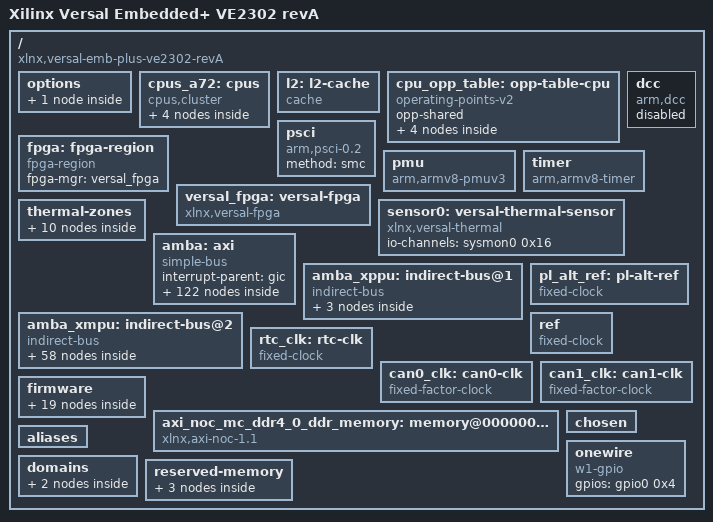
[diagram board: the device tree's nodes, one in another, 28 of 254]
/dts-v1/;
/ {
        compatible = "xlnx,versal-emb-plus-ve2302-revA", "xlnx,versal-emb-plus-ve2302", "xlnx,versal";
        #address-cells = <0x2>;
        #size-cells = <0x2>;
        model = "Xilinx Versal Embedded+ VE2302 revA";
        board = "v80";
        device_id = "xcv80";
        slrcount = <0x3>;
        family = "Versal";
        speed_grade = "2MHP";

        options {

                u-boot {
                        compatible = "u-boot,config";
                        bootscr-address = /bits/ 64 <0x20000000>;
                };
        };

        cpus_a72: cpus {
                phandle = <0xc3>;
                #address-cells = <0x1>;
                #size-cells = <0x0>;
                compatible = "cpus,cluster";
                #ranges-address-cells = <0x2>;
                #ranges-size-cells = <0x2>;

                psv_cortexa72_0: cpu@0 {
                        phandle = <0xbd>;
                        compatible = "arm,cortex-a72", "arm,armv8";
                        device_type = "cpu";
                        enable-method = "psci";
                        operating-points-v2 = <&cpu_opp_table>;
                        reg = <0x0>;
                        cpu-idle-states = <&CPU_SLEEP_0>;
                        power-domains = <&versal_firmware 0x18110003>;
                        d-cache-size = <0x8000>;
                        d-cache-line-size = <0x40>;
                        d-cache-sets = <0x100>;
                        i-cache-size = <0xc000>;
                        i-cache-line-size = <0x40>;
                        i-cache-sets = <0x100>;
                        next-level-cache = <&l2>;
                        clocks = <&versal_clk 0x4d>;
                        xlnx,timestamp-clk-freq = <0x5f5e100>;
                        xlnx,pss-ref-clk-freq = <0x1fca055>;
                        stamp-frequency = <0x5f5e100>;
                        xlnx,ip-name = "psv_cortexa72";
                        xlnx,cpu-clk-freq-hz = <0x62590006>;
                        cpu-frequency = <0x62590006>;
                        bus-handle = <0x1>;
                };

                psv_cortexa72_1: cpu@1 {
                        phandle = <0xbf>;
                        compatible = "arm,cortex-a72", "arm,armv8";
                        device_type = "cpu";
                        enable-method = "psci";
                        operating-points-v2 = <&cpu_opp_table>;
                        reg = <0x1>;
                        cpu-idle-states = <&CPU_SLEEP_0>;
                        power-domains = <&versal_firmware 0x18110004>;
                        d-cache-size = <0x8000>;
                        d-cache-line-size = <0x40>;
                        d-cache-sets = <0x100>;
                        i-cache-size = <0xc000>;
                        i-cache-line-size = <0x40>;
                        i-cache-sets = <0x100>;
                        next-level-cache = <&l2>;
                        xlnx,timestamp-clk-freq = <0x5f5e100>;
                        xlnx,pss-ref-clk-freq = <0x1fca055>;
                        stamp-frequency = <0x5f5e100>;
                        xlnx,ip-name = "psv_cortexa72";
                        xlnx,cpu-clk-freq-hz = <0x62590006>;
                        cpu-frequency = <0x62590006>;
                        bus-handle = <0x1>;
                };

                idle-states {
                        entry-method = "psci";

                        CPU_SLEEP_0: cpu-sleep-0 {
                                phandle = <0x8c>;
                                compatible = "arm,idle-state";
                                arm,psci-suspend-param = <0x40000000>;
                                local-timer-stop;
                                entry-latency-us = <0x12c>;
                                exit-latency-us = <0x258>;
                                min-residency-us = <0x2710>;
                        };
                };
        };

        l2: l2-cache {
                phandle = <0x8e>;
                compatible = "cache";
                cache-level = <0x2>;
                cache-size = <0x100000>;
                cache-line-size = <0x40>;
                cache-sets = <0x1000>;
                cache-unified;
        };

        cpu_opp_table: opp-table-cpu {
                phandle = <0x8b>;
                compatible = "operating-points-v2";
                opp-shared;

                opp-1650000000 {
                        opp-hz = /bits/ 64 <0x62590080>;
                        clock-latency-ns = <0x7a120>;
                        opp-microvolt = <0xf4240>;
                };

                opp-825000000 {
                        opp-hz = /bits/ 64 <0x312c8040>;
                        clock-latency-ns = <0x7a120>;
                        opp-microvolt = <0xf4240>;
                };

                opp-550000000 {
                        opp-hz = /bits/ 64 <0x20c85580>;
                        clock-latency-ns = <0x7a120>;
                        opp-microvolt = <0xf4240>;
                };

                opp-412500000 {
                        opp-hz = /bits/ 64 <0x18964020>;
                        clock-latency-ns = <0x7a120>;
                        opp-microvolt = <0xf4240>;
                };
        };

        dcc: dcc {
                phandle = <0xcc>;
                compatible = "arm,dcc";
                status = "disabled";
                bootph-all;
        };

        fpga: fpga-region {
                phandle = <0xcd>;
                compatible = "fpga-region";
                fpga-mgr = <&versal_fpga>;
                #address-cells = <0x2>;
                #size-cells = <0x2>;
        };

        psci: psci {
                phandle = <0xce>;
                compatible = "arm,psci-0.2";
                method = "smc";
        };

        pmu {
                compatible = "arm,armv8-pmuv3";
                interrupt-parent = <&gic>;
                interrupts = <0x1 0x7 0x304>;
        };

        timer: timer {
                phandle = <0xcf>;
                compatible = "arm,armv8-timer";
                interrupt-parent = <&gic>;
                interrupts = <0x1 0xd 0x4 0x1 0xe 0x4 0x1 0xb 0x4 0x1 0xa 0x4>;
        };

        versal_fpga: versal-fpga {
                phandle = <0xa8>;
                compatible = "xlnx,versal-fpga";
        };

        sensor0: versal-thermal-sensor {
                phandle = <0xaa>;
                compatible = "xlnx,versal-thermal";
                #thermal-sensor-cells = <0x1>;
                io-channels = <&sysmon0 0x16>;
                io-channel-names = "sysmon-temp-channel";
        };

        thermal-zones {

                versal_thermal: versal-thermal {
                        phandle = <0xd0>;
                        polling-delay-passive = <0xfa>;
                        polling-delay = <0x3e8>;
                        thermal-sensors = <&sensor0 0x0>;

                        trips {

                                temp_alert: temp-alert {
                                        phandle = <0xd1>;
                                        temperature = <0x11170>;
                                        hysteresis = <0x0>;
                                        type = "passive";
                                };

                                ot_crit: ot-crit {
                                        phandle = <0xd2>;
                                        temperature = <0x1e848>;
                                        hysteresis = <0x0>;
                                        type = "critical";
                                };
                        };

                        cooling-maps {
                        };
                };

                versal_thermal_aie: versal-aie-thermal {
                        phandle = <0xd3>;
                        polling-delay-passive = <0xfa>;
                        polling-delay = <0x3e8>;
                        thermal-sensors = <&sensor0 0x1>;

                        trips {

                                temp_alert_aie: temp-alert-aie {
                                        phandle = <0xd4>;
                                        temperature = <0x11170>;
                                        hysteresis = <0x0>;
                                        type = "passive";
                                };

                                ot_crit_aie: ot-crit-aie {
                                        phandle = <0xd5>;
                                        temperature = <0x1e848>;
                                        hysteresis = <0x0>;
                                        type = "critical";
                                };
                        };

                        cooling-maps {
                        };
                };
        };

        amba: axi {
                phandle = <0x1>;
                compatible = "simple-bus";
                #address-cells = <0x2>;
                #size-cells = <0x2>;
                ranges;
                interrupt-parent = <&gic>;
                bootph-all;

                can0: can@ff060000 {
                        phandle = <0xd6>;
                        compatible = "xlnx,canfd-2.0";
                        status = "disabled";
                        reg = <0x0 0xff060000 0x0 0x6000>;
                        interrupts = <0x0 0x14 0x4>;
                        interrupt-parent = <&gic>;
                        clock-names = "can_clk", "s_axi_aclk";
                        rx-fifo-depth = <0x40>;
                        tx-mailbox-count = <0x20>;
                        clocks = <&can0_clk>,
                         <&versal_clk 0x52>;
                        power-domains = <&versal_firmware 0x1822401f>;
                };

                can1: can@ff070000 {
                        phandle = <0xd7>;
                        compatible = "xlnx,canfd-2.0";
                        status = "disabled";
                        reg = <0x0 0xff070000 0x0 0x6000>;
                        interrupts = <0x0 0x15 0x4>;
                        interrupt-parent = <&gic>;
                        clock-names = "can_clk", "s_axi_aclk";
                        rx-fifo-depth = <0x40>;
                        tx-mailbox-count = <0x20>;
                        clocks = <&can1_clk>,
                         <&versal_clk 0x52>;
                        power-domains = <&versal_firmware 0x18224020>;
                };

                cci: cci@fd000000 {
                        phandle = <0x5a>;
                        compatible = "arm,cci-500";
                        status = "okay";
                        reg = <0x0 0xfd000000 0x0 0x10000>;
                        ranges = <0x0 0x0 0xfd000000 0xa0000>;
                        #address-cells = <0x1>;
                        #size-cells = <0x1>;
                        xlnx,ip-name = "psv_fpd_maincci";

                        cci_pmu: pmu@10000 {
                                phandle = <0xd8>;
                                compatible = "arm,cci-500-pmu,r0";
                                reg = <0x10000 0x90000>;
                                interrupt-parent = <&gic>;
                                interrupts = <0x0 0x6a 0x4 0x0 0x6a 0x4 0x0 0x6a 0x4 0x0 0x6a 0x4 0x0 0x6a 0x4 0x0 0x6a 0x4 0x0 0x6a 0x4 0x0 0x6a 0x4>;
                        };
                };

                lpd_dma_chan0: dma-controller@ffa80000 {
                        phandle = <0x7c>;
                        compatible = "xlnx,zynqmp-dma-1.0";
                        status = "okay";
                        reg = <0x0 0xffa80000 0x0 0x1000>;
                        interrupts = <0x0 0x3c 0x4>;
                        interrupt-parent = <&gic>;
                        clock-names = "clk_main", "clk_apb";
                        xlnx,dma-type = <0x1>;
                        #dma-cells = <0x1>;
                        xlnx,bus-width = <0x40>;
                        clocks = <&versal_clk 0x51>,
                         <&versal_clk 0x52>;
                        power-domains = <&versal_firmware 0x18224035>;
                        xlnx,is-cache-coherent = <0x0>;
                        xlnx,ip-name = "psv_adma";
                        xlnx,dma-mode = <0x1>;
                };

                lpd_dma_chan1: dma-controller@ffa90000 {
                        phandle = <0x7d>;
                        compatible = "xlnx,zynqmp-dma-1.0";
                        status = "okay";
                        reg = <0x0 0xffa90000 0x0 0x1000>;
                        interrupts = <0x0 0x3d 0x4>;
                        interrupt-parent = <&gic>;
                        clock-names = "clk_main", "clk_apb";
                        xlnx,dma-type = <0x1>;
                        #dma-cells = <0x1>;
                        xlnx,bus-width = <0x40>;
                        clocks = <&versal_clk 0x51>,
                         <&versal_clk 0x52>;
                        power-domains = <&versal_firmware 0x18224036>;
                        xlnx,is-cache-coherent = <0x0>;
                        xlnx,ip-name = "psv_adma";
                        xlnx,dma-mode = <0x1>;
                };

                lpd_dma_chan2: dma-controller@ffaa0000 {
                        phandle = <0x7e>;
                        compatible = "xlnx,zynqmp-dma-1.0";
                        status = "okay";
                        reg = <0x0 0xffaa0000 0x0 0x1000>;
                        interrupts = <0x0 0x3e 0x4>;
                        interrupt-parent = <&gic>;
                        clock-names = "clk_main", "clk_apb";
                        xlnx,dma-type = <0x1>;
                        #dma-cells = <0x1>;
                        xlnx,bus-width = <0x40>;
                        clocks = <&versal_clk 0x51>,
                         <&versal_clk 0x52>;
                        power-domains = <&versal_firmware 0x18224037>;
                        xlnx,is-cache-coherent = <0x0>;
                        xlnx,ip-name = "psv_adma";
                        xlnx,dma-mode = <0x1>;
                };

                lpd_dma_chan3: dma-controller@ffab0000 {
                        phandle = <0x7f>;
                        compatible = "xlnx,zynqmp-dma-1.0";
                        status = "okay";
                        reg = <0x0 0xffab0000 0x0 0x1000>;
                        interrupts = <0x0 0x3f 0x4>;
                        interrupt-parent = <&gic>;
                        clock-names = "clk_main", "clk_apb";
                        xlnx,dma-type = <0x1>;
                        #dma-cells = <0x1>;
                        xlnx,bus-width = <0x40>;
                        clocks = <&versal_clk 0x51>,
                         <&versal_clk 0x52>;
                        power-domains = <&versal_firmware 0x18224038>;
                        xlnx,is-cache-coherent = <0x0>;
                        xlnx,ip-name = "psv_adma";
                        xlnx,dma-mode = <0x1>;
                };

                lpd_dma_chan4: dma-controller@ffac0000 {
                        phandle = <0x80>;
                        compatible = "xlnx,zynqmp-dma-1.0";
                        status = "okay";
                        reg = <0x0 0xffac0000 0x0 0x1000>;
                        interrupts = <0x0 0x40 0x4>;
                        interrupt-parent = <&gic>;
                        clock-names = "clk_main", "clk_apb";
                        xlnx,dma-type = <0x1>;
                        #dma-cells = <0x1>;
                        xlnx,bus-width = <0x40>;
                        clocks = <&versal_clk 0x51>,
                         <&versal_clk 0x52>;
                        power-domains = <&versal_firmware 0x18224039>;
                        xlnx,is-cache-coherent = <0x0>;
                        xlnx,ip-name = "psv_adma";
                        xlnx,dma-mode = <0x1>;
                };

                lpd_dma_chan5: dma-controller@ffad0000 {
                        phandle = <0x81>;
                        compatible = "xlnx,zynqmp-dma-1.0";
                        status = "okay";
                        reg = <0x0 0xffad0000 0x0 0x1000>;
                        interrupts = <0x0 0x41 0x4>;
                        interrupt-parent = <&gic>;
                        clock-names = "clk_main", "clk_apb";
                        xlnx,dma-type = <0x1>;
                        #dma-cells = <0x1>;
                        xlnx,bus-width = <0x40>;
                        clocks = <&versal_clk 0x51>,
                         <&versal_clk 0x52>;
                        power-domains = <&versal_firmware 0x1822403a>;
                        xlnx,is-cache-coherent = <0x0>;
                        xlnx,ip-name = "psv_adma";
                        xlnx,dma-mode = <0x1>;
                };

                lpd_dma_chan6: dma-controller@ffae0000 {
                        phandle = <0x82>;
                        compatible = "xlnx,zynqmp-dma-1.0";
                        status = "okay";
                        reg = <0x0 0xffae0000 0x0 0x1000>;
                        interrupts = <0x0 0x42 0x4>;
                        interrupt-parent = <&gic>;
                        clock-names = "clk_main", "clk_apb";
                        xlnx,dma-type = <0x1>;
                        #dma-cells = <0x1>;
                        xlnx,bus-width = <0x40>;
                        clocks = <&versal_clk 0x51>,
                         <&versal_clk 0x52>;
                        power-domains = <&versal_firmware 0x1822403b>;
                        xlnx,is-cache-coherent = <0x0>;
                        xlnx,ip-name = "psv_adma";
                        xlnx,dma-mode = <0x1>;
                };

                lpd_dma_chan7: dma-controller@ffaf0000 {
                        phandle = <0x83>;
                        compatible = "xlnx,zynqmp-dma-1.0";
                        status = "okay";
                        reg = <0x0 0xffaf0000 0x0 0x1000>;
                        interrupts = <0x0 0x43 0x4>;
                        interrupt-parent = <&gic>;
                        clock-names = "clk_main", "clk_apb";
                        xlnx,dma-type = <0x1>;
                        #dma-cells = <0x1>;
                        xlnx,bus-width = <0x40>;
                        clocks = <&versal_clk 0x51>,
                         <&versal_clk 0x52>;
                        power-domains = <&versal_firmware 0x1822403c>;
                        xlnx,is-cache-coherent = <0x0>;
                        xlnx,ip-name = "psv_adma";
                        xlnx,dma-mode = <0x1>;
                };

                gem0: ethernet@ff0c0000 {
                        phandle = <0xd9>;
                        compatible = "xlnx,versal-gem", "cdns,gem";
                        status = "disabled";
                        reg = <0x0 0xff0c0000 0x0 0x1000>;
                        interrupts = <0x0 0x38 0x4 0x0 0x38 0x4>;
                        interrupt-parent = <&gic>;
                        clock-names = "pclk", "hclk", "tx_clk", "rx_clk", "tsu_clk";
                        #address-cells = <0x1>;
                        #size-cells = <0x0>;
                        clocks = <&versal_clk 0x52>,
                         <&versal_clk 0x58>,
                         <&versal_clk 0x31>,
                         <&versal_clk 0x30>,
                         <&versal_clk 0x2b>;
                        power-domains = <&versal_firmware 0x18224019>;
                };

                gem1: ethernet@ff0d0000 {
                        phandle = <0xda>;
                        compatible = "xlnx,versal-gem", "cdns,gem";
                        status = "disabled";
                        reg = <0x0 0xff0d0000 0x0 0x1000>;
                        interrupts = <0x0 0x3a 0x4 0x0 0x3a 0x4>;
                        interrupt-parent = <&gic>;
                        clock-names = "pclk", "hclk", "tx_clk", "rx_clk", "tsu_clk";
                        #address-cells = <0x1>;
                        #size-cells = <0x0>;
                        clocks = <&versal_clk 0x52>,
                         <&versal_clk 0x59>,
                         <&versal_clk 0x33>,
                         <&versal_clk 0x32>,
                         <&versal_clk 0x2b>;
                        power-domains = <&versal_firmware 0x1822401a>;
                };

                gpio0: gpio@ff0b0000 {
                        phandle = <0x6d>;
                        compatible = "xlnx,versal-gpio-1.0";
                        status = "okay";
                        reg = <0x0 0xff0b0000 0x0 0x1000>;
                        interrupts = <0x0 0xd 0x4>;
                        interrupt-parent = <&gic>;
                        #gpio-cells = <0x2>;
                        gpio-controller;
                        #interrupt-cells = <0x2>;
                        interrupt-controller;
                        clocks = <&versal_clk 0x52>;
                        power-domains = <&versal_firmware 0x18224023>;
                        xlnx,ps-gpio-emio-peripheral-enable = <0x0>;
                        xlnx,ip-name = "psv_gpio";
                        emio-gpio-width = "";
                        gpio-line-names = "GPIO_LED2", "GPIO_LED3", "GPIO_LED4", "", "1WIRE", "", "FUSA", "", "EGPIO", "AGPIO", "I2C0_SCL", "I2C0_SDA", "", "", "", "", "", "", "", "", "", "", "", "", "3V3_MON_N", "3V3_MON_P", "", "", "", "", "", "", "", "", "", "", "", "", "", "", "", "", "", "", "", "", "", "", "", "", "", "", "", "", "", "", "";
                };

                gpio1: gpio@f1020000 {
                        phandle = <0x2f>;
                        compatible = "xlnx,pmc-gpio-1.0";
                        status = "disabled";
                        reg = <0x0 0xf1020000 0x0 0x1000>;
                        interrupts = <0x0 0x7a 0x4>;
                        interrupt-parent = <&gic>;
                        #gpio-cells = <0x2>;
                        gpio-controller;
                        #interrupt-cells = <0x2>;
                        interrupt-controller;
                        clocks = <&versal_clk 0x3d>;
                        power-domains = <&versal_firmware 0x1822402c>;
                        xlnx,ip-name = "psv_pmc_gpio";
                        xlnx,pmc-gpio-emio-peripheral-enable = <0x0>;
                };

                i2c0: i2c@ff020000 {
                        phandle = <0x68>;
                        compatible = "cdns,i2c-r1p14";
                        status = "okay";
                        reg = <0x0 0xff020000 0x0 0x1000>;
                        interrupts = <0x0 0xe 0x4>;
                        interrupt-parent = <&gic>;
                        clock-frequency = <0x186a0>;
                        #address-cells = <0x1>;
                        #size-cells = <0x0>;
                        clocks = <&versal_clk 0x62>;
                        power-domains = <&versal_firmware 0x1822401d>;
                        xlnx,clock-freq = <0x5f5e100>;
                        xlnx,i2c-clk-freq-hz = <0x5f5e100>;
                        xlnx,ip-name = "psv_i2c";
                        xlnx,iic-board-interface = "custom";
                };

                i2c1: i2c@ff030000 {
                        phandle = <0x69>;
                        compatible = "cdns,i2c-r1p14";
                        status = "okay";
                        reg = <0x0 0xff030000 0x0 0x1000>;
                        interrupts = <0x0 0xf 0x4>;
                        interrupt-parent = <&gic>;
                        clock-frequency = <0x186a0>;
                        #address-cells = <0x1>;
                        #size-cells = <0x0>;
                        clocks = <&versal_clk 0x63>;
                        power-domains = <&versal_firmware 0x1822401e>;
                        xlnx,clock-freq = <0x5f5e100>;
                        xlnx,i2c-clk-freq-hz = <0x5f5e100>;
                        xlnx,ip-name = "psv_i2c";
                        xlnx,iic-board-interface = "custom";
                };

                i2c2: i2c@f1000000 {
                        phandle = <0xdb>;
                        compatible = "cdns,i2c-r1p14";
                        status = "disabled";
                        reg = <0x0 0xf1000000 0x0 0x1000>;
                        interrupts = <0x0 0x7b 0x4>;
                        interrupt-parent = <&gic>;
                        clock-frequency = <0x186a0>;
                        #address-cells = <0x1>;
                        #size-cells = <0x0>;
                        clocks = <&versal_clk 0x3e>;
                        power-domains = <&versal_firmware 0x1822402d>;
                };

                mc0: memory-controller@f6150000 {
                        phandle = <0xdc>;
                        compatible = "xlnx,versal-ddrmc";
                        status = "okay";
                        reg = <0x0 0xf6150000 0x0 0x2000 0x0 0xf6070000 0x0 0x20000>;
                        reg-names = "base", "noc";
                        interrupts = <0x0 0x93 0x4>;
                        interrupt-parent = <&gic>;
                };

                mc1: memory-controller@f62c0000 {
                        phandle = <0xdd>;
                        compatible = "xlnx,versal-ddrmc";
                        status = "okay";
                        reg = <0x0 0xf62c0000 0x0 0x2000 0x0 0xf6210000 0x0 0x20000>;
                        reg-names = "base", "noc";
                        interrupts = <0x0 0x93 0x4>;
                        interrupt-parent = <&gic>;
                };

                mc2: memory-controller@f6430000 {
                        phandle = <0xde>;
                        compatible = "xlnx,versal-ddrmc";
                        status = "disabled";
                        reg = <0x0 0xf6430000 0x0 0x2000 0x0 0xf6380000 0x0 0x20000>;
                        reg-names = "base", "noc";
                        interrupts = <0x0 0x93 0x4>;
                        interrupt-parent = <&gic>;
                };

                mc3: memory-controller@f65a0000 {
                        phandle = <0xdf>;
                        compatible = "xlnx,versal-ddrmc";
                        status = "disabled";
                        reg = <0x0 0xf65a0000 0x0 0x2000 0x0 0xf64f0000 0x0 0x20000>;
                        reg-names = "base", "noc";
                        interrupts = <0x0 0x93 0x4>;
                        interrupt-parent = <&gic>;
                };

                ocm: memory-controller@ff960000 {
                        phandle = <0xe0>;
                        compatible = "xlnx,zynqmp-ocmc-1.0";
                        reg = <0x0 0xff960000 0x0 0x1000>;
                        interrupts = <0x0 0xa 0x4>;
                        interrupt-parent = <&gic>;
                };

                rtc: rtc@f12a0000 {
                        phandle = <0x41>;
                        compatible = "xlnx,zynqmp-rtc";
                        status = "okay";
                        reg = <0x0 0xf12a0000 0x0 0x100>;
                        interrupt-names = "alarm", "sec";
                        interrupts = <0x0 0x8e 0x4 0x0 0x8f 0x4>;
                        interrupt-parent = <&gic>;
                        clocks = <&rtc_clk>;
                        clock-names = "rtc";
                        power-domains = <&versal_firmware 0x18224034>;
                        xlnx,ip-name = "psv_pmc_rtc";
                };

                sdhci0: mmc@f1040000 {
                        phandle = <0x30>;
                        compatible = "xlnx,versal-8.9a", "arasan,sdhci-8.9a";
                        status = "disabled";
                        reg = <0x0 0xf1040000 0x0 0x10000>;
                        interrupts = <0x0 0x7e 0x4>;
                        interrupt-parent = <&gic>;
                        clock-names = "clk_xin", "clk_ahb", "gate";
                        #clock-cells = <0x1>;
                        clock-output-names = "clk_out_sd0", "clk_in_sd0";
                        clocks = <&versal_clk 0x3b>,
                         <&versal_clk 0x52>,
                         <&versal_clk 0x4a>;
                        power-domains = <&versal_firmware 0x1822402e>;
                        xlnx,sd-board-interface = "custom";
                        xlnx,is-cache-coherent = <0x0>;
                        xlnx,clk-50-ddr-otap-dly = <0x5>;
                        xlnx,clk-50-sdr-itap-dly = <0x2c>;
                        xlnx,has-emio = <0x0>;
                        clock-frequency = <0xbebc200>;
                        xlnx,clk-100-sdr-otap-dly = <0x0>;
                        xlnx,mio-bank = <0x0>;
                        xlnx,ip-name = "psv_pmc_sd";
                        xlnx,bus-width = <0x8>;
                        xlnx,card-detect = <0x0>;
                        xlnx,has-wp = <0x0>;
                        xlnx,has-cd = <0x0>;
                        xlnx,slot-type = <0x1>;
                        xlnx,clk-50-sdr-otap-dly = <0x5>;
                        xlnx,clk-50-ddr-itap-dly = <0x1e>;
                        xlnx,has-power = <0x0>;
                        xlnx,clk-200-sdr-otap-dly = <0x2>;
                        xlnx,sdio-clk-freq-hz = <0xbebc200>;
                        xlnx,write-protect = <0x0>;
                };

                sdhci1: mmc@f1050000 {
                        phandle = <0xe1>;
                        compatible = "xlnx,versal-8.9a", "arasan,sdhci-8.9a";
                        status = "disabled";
                        reg = <0x0 0xf1050000 0x0 0x10000>;
                        interrupts = <0x0 0x80 0x4>;
                        interrupt-parent = <&gic>;
                        clock-names = "clk_xin", "clk_ahb", "gate";
                        #clock-cells = <0x1>;
                        clock-output-names = "clk_out_sd1", "clk_in_sd1";
                        clocks = <&versal_clk 0x3c>,
                         <&versal_clk 0x52>,
                         <&versal_clk 0x4a>;
                        power-domains = <&versal_firmware 0x1822402f>;
                };

                serial0: serial@ff000000 {
                        phandle = <0x66>;
                        compatible = "arm,pl011", "arm,primecell";
                        status = "disabled";
                        reg = <0x0 0xff000000 0x0 0x1000>;
                        interrupts = <0x0 0x12 0x4>;
                        interrupt-parent = <&gic>;
                        reg-io-width = <0x4>;
                        clock-names = "uartclk", "apb_pclk";
                        bootph-all;
                        clocks = <&versal_clk 0x5c>,
                         <&versal_clk 0x52>;
                        power-domains = <&versal_firmware 0x18224021>;
                        xlnx,has-modem = <0x0>;
                        xlnx,uart-clk-freq-hz = <0x5f5e100>;
                        port-number = <0x0>;
                        xlnx,ip-name = "psv_sbsauart";
                        xlnx,uart-board-interface = "custom";
                        xlnx,baudrate = <0x1c200>;
                        cts-override;
                        u-boot,dm-pre-reloc;
                        device_type = "serial";
                        xlnx,clock-freq = <0x5f5e100>;
                };

                serial1: serial@ff010000 {
                        phandle = <0x67>;
                        compatible = "arm,pl011", "arm,primecell";
                        status = "okay";
                        reg = <0x0 0xff010000 0x0 0x1000>;
                        interrupts = <0x0 0x13 0x4>;
                        interrupt-parent = <&gic>;
                        reg-io-width = <0x4>;
                        clock-names = "uartclk", "apb_pclk";
                        bootph-all;
                        clocks = <&versal_clk 0x5d>,
                         <&versal_clk 0x52>;
                        power-domains = <&versal_firmware 0x18224022>;
                        xlnx,has-modem = <0x0>;
                        xlnx,uart-clk-freq-hz = <0x5f5e100>;
                        port-number = <0x0>;
                        xlnx,ip-name = "psv_sbsauart";
                        xlnx,uart-board-interface = "custom";
                        xlnx,baudrate = <0x1c200>;
                        cts-override;
                        u-boot,dm-pre-reloc;
                        device_type = "serial";
                        xlnx,clock-freq = <0x5f5e100>;
                };

                smmu: iommu@fd800000 {
                        phandle = <0x65>;
                        compatible = "arm,mmu-500";
                        status = "okay";
                        reg = <0x0 0xfd800000 0x0 0x40000>;
                        stream-match-mask = <0x7c00>;
                        #iommu-cells = <0x1>;
                        #global-interrupts = <0x1>;
                        interrupts = <0x0 0x6b 0x4 0x0 0x6b 0x4 0x0 0x6b 0x4 0x0 0x6b 0x4 0x0 0x6b 0x4 0x0 0x6b 0x4 0x0 0x6b 0x4 0x0 0x6b 0x4 0x0 0x6b 0x4 0x0 0x6b 0x4 0x0 0x6b 0x4 0x0 0x6b 0x4 0x0 0x6b 0x4 0x0 0x6b 0x4 0x0 0x6b 0x4 0x0 0x6b 0x4 0x0 0x6b 0x4 0x0 0x6b 0x4 0x0 0x6b 0x4 0x0 0x6b 0x4 0x0 0x6b 0x4 0x0 0x6b 0x4 0x0 0x6b 0x4 0x0 0x6b 0x4 0x0 0x6b 0x4 0x0 0x6b 0x4 0x0 0x6b 0x4 0x0 0x6b 0x4 0x0 0x6b 0x4 0x0 0x6b 0x4 0x0 0x6b 0x4 0x0 0x6b 0x4 0x0 0x6b 0x4>;
                        interrupt-parent = <&gic>;
                        xlnx,ip-name = "psv_fpd_smmutcu";
                };

                ospi: spi@f1010000 {
                        phandle = <0x2e>;
                        compatible = "xlnx,versal-ospi-1.0", "cdns,qspi-nor";
                        status = "disabled";
                        reg = <0x0 0xf1010000 0x0 0x10000 0x0 0xc0000000 0x0 0x20000000>;
                        interrupts = <0x0 0x7c 0x4>;
                        interrupt-parent = <&gic>;
                        cdns,fifo-depth = <0x100>;
                        cdns,fifo-width = <0x4>;
                        cdns,is-dma = <0x1>;
                        cdns,trigger-address = <0xc0000000>;
                        #address-cells = <0x1>;
                        #size-cells = <0x0>;
                        clocks = <&versal_clk 0x3a>;
                        power-domains = <&versal_firmware 0x1822402a>;
                        reset-names = "qspi";
                        resets = <&versal_reset 0xc10402e>;
                        is-stacked = <0x0>;
                        xlnx,is-cache-coherent = <0x0>;
                        xlnx,clock-freq = <0xbebc200>;
                        xlnx,ip-name = "psv_pmc_ospi";
                        xlnx,ospi-clk-freq-hz = <0xbebc200>;
                        is-dual = <0x0>;
                        xlnx,ospi-mode = <0x0>;
                };

                qspi: spi@f1030000 {
                        phandle = <0xe2>;
                        compatible = "xlnx,versal-qspi-1.0";
                        status = "disabled";
                        reg = <0x0 0xf1030000 0x0 0x1000>;
                        interrupts = <0x0 0x7d 0x4>;
                        interrupt-parent = <&gic>;
                        clock-names = "ref_clk", "pclk";
                        #address-cells = <0x1>;
                        #size-cells = <0x0>;
                        clocks = <&versal_clk 0x39>,
                         <&versal_clk 0x52>;
                        power-domains = <&versal_firmware 0x1822402b>;
                };

                spi0: spi@ff040000 {
                        phandle = <0x6a>;
                        compatible = "cdns,spi-r1p6";
                        status = "okay";
                        reg = <0x0 0xff040000 0x0 0x1000>;
                        interrupts = <0x0 0x10 0x4>;
                        interrupt-parent = <&gic>;
                        clock-names = "ref_clk", "pclk";
                        #address-cells = <0x1>;
                        #size-cells = <0x0>;
                        clocks = <&versal_clk 0x5e>,
                         <&versal_clk 0x52>;
                        power-domains = <&versal_firmware 0x1822401b>;
                        xlnx,spi-board-interface = "custom";
                        xlnx,has-ss0 = <0x1>;
                        xlnx,ip-name = "psv_spi";
                        xlnx,has-ss1 = <0x0>;
                        num-cs = <0x1>;
                        xlnx,spi-clk-freq-hz = <0xbebc200>;
                        xlnx,has-ss2 = <0x0>;
                };

                spi1: spi@ff050000 {
                        phandle = <0xe3>;
                        compatible = "cdns,spi-r1p6";
                        status = "disabled";
                        reg = <0x0 0xff050000 0x0 0x1000>;
                        interrupts = <0x0 0x11 0x4>;
                        interrupt-parent = <&gic>;
                        clock-names = "ref_clk", "pclk";
                        #address-cells = <0x1>;
                        #size-cells = <0x0>;
                        clocks = <&versal_clk 0x5f>,
                         <&versal_clk 0x52>;
                        power-domains = <&versal_firmware 0x1822401c>;
                };

                sysmon0: sysmon@f1270000 {
                        phandle = <0x40>;
                        compatible = "xlnx,versal-sysmon";
                        #io-channel-cells = <0x1>;
                        reg = <0x0 0xf1270000 0x0 0x4000>;
                        interrupts = <0x0 0x90 0x4>;
                        xlnx,numchannels = [16];
                        #address-cells = <0x2>;
                        #size-cells = <0x2>;
                        xlnx,nodeid = <0x18224055>;
                        xlnx,sat-63-desc = "PS , FPD , satellite";
                        xlnx,sat-1-desc = "PMC , system , ADC";
                        xlnx,sat-17-x = <0x35e5>;
                        xlnx,sat-9-x = <0x6ed4>;
                        xlnx,sat-20-desc = "HBM , Satellite , (right)";
                        xlnx,sat-19-desc = "VNOC , satellite";
                        xlnx,sat-17-y = <0x676f>;
                        xlnx,sat-9-y = <0x772d>;
                        xlnx,sat-22-x = <0x21a7>;
                        xlnx,meas-7-slr-number = <0x0>;
                        xlnx,meas-0-root-id = <0x6>;
                        xlnx,meas-16-slr-number = <0x0>;
                        xlnx,sat-22-y = <0x7362>;
                        xlnx,meas-10-root-id = <0x1>;
                        xlnx,ip-name = "psv_pmc_sysmon";
                        xlnx,meas-1-root-id = <0x8>;
                        xlnx,sat-16-desc = "HBM , Satellite , (left)";
                        xlnx,meas-11-root-id = <0x2>;
                        xlnx,meas-2-root-id = <0x5>;
                        xlnx,meas-3-root-id = <0x3>;
                        xlnx,meas-11-slr-number = <0x0>;
                        xlnx,meas-12-root-id = <0xd>;
                        xlnx,meas-2-slr-number = <0x0>;
                        xlnx,sat-9-desc = "Clocking , column , satellite";
                        xlnx,sat-26-x = <0xf56>;
                        xlnx,meas-4-root-id = <0x4>;
                        xlnx,meas-13-root-id = <0xe>;
                        xlnx,sat-28-desc = "Clocking , column , satellite";
                        xlnx,sat-26-y = <0x7cf2>;
                        xlnx,sat-10-x = <0x6ed4>;
                        xlnx,meas-5-root-id = <0x7>;
                        xlnx,meas-14-root-id = <0xf>;
                        xlnx,sat-64-x = <0x56b>;
                        xlnx,sat-2-x = <0x56b>;
                        xlnx,sat-10-y = <0x70fe>;
                        xlnx,meas-6-root-id = <0x9>;
                        xlnx,meas-15-root-id = <0x14>;
                        xlnx,sat-64-y = <0xf11>;
                        xlnx,sat-2-y = <0x649d>;
                        xlnx,sat-13-desc = "VNOC , satellite";
                        xlnx,meas-7-root-id = <0xa>;
                        xlnx,meas-16-root-id = <0x15>;
                        xlnx,meas-8-root-id = <0xc>;
                        xlnx,meas-17-root-id = <0x12>;
                        xlnx,sat-6-desc = "HBM , Satellite , (right)";
                        xlnx,sat-14-x = <0x4a23>;
                        xlnx,meas-9-root-id = <0x0>;
                        xlnx,meas-18-root-id = <0x13>;
                        xlnx,sat-6-x = <0x5f7a>;
                        xlnx,sat-25-desc = "Clocking , column , satellite";
                        xlnx,sat-14-y = <0x7362>;
                        xlnx,meas-19-root-id = <0x16>;
                        xlnx,meas-20-root-id = <0x17>;
                        xlnx,sat-6-y = <0x9780>;
                        xlnx,meas-19-slr-number = <0x0>;
                        xlnx,meas-20-slr-number = <0x0>;
                        xlnx,meas-21-root-id = <0xb>;
                        xlnx,sat-10-desc = "Clocking , column , satellite";
                        xlnx,sat-18-x = <0x35e5>;
                        xlnx,sat-3-desc = "VNOC , satellite";
                        xlnx,sat-18-y = <0x7362>;
                        xlnx,meas-5-slr-number = <0x0>;
                        xlnx,meas-14-slr-number = <0x0>;
                        xlnx,sat-22-desc = "VNOC , satellite";
                        xlnx,sat-23-x = <0x21a7>;
                        xlnx,meas-0-slr-number = <0x0>;
                        xlnx,sat-23-y = <0x7f56>;
                        xlnx,sat-18-desc = "VNOC , satellite";
                        xlnx,sat-27-x = <0xf56>;
                        xlnx,sat-27-y = <0x772d>;
                        xlnx,sat-11-x = <0x6ed4>;
                        xlnx,sat-3-x = <0x5e61>;
                        xlnx,sat-11-y = <0x6b39>;
                        xlnx,sat-3-y = <0x676f>;
                        status = "okay";
                        xlnx,sat-15-desc = "VNOC , satellite";
                        xlnx,meas-8-slr-number = <0x0>;
                        xlnx,meas-17-slr-number = <0x0>;
                        xlnx,sat-15-x = <0x4a23>;
                        xlnx,sat-8-desc = "Clocking , column , satellite";
                        xlnx,sat-7-x = <0x6ed4>;
                        xlnx,sat-15-y = <0x7f56>;
                        xlnx,sat-7-y = <0x8321>;
                        xlnx,sat-27-desc = "Clocking , column , satellite";
                        xlnx,meas-3-slr-number = <0x0>;
                        xlnx,meas-12-slr-number = <0x0>;
                        xlnx,sat-20-x = <0x3441>;
                        xlnx,sat-19-x = <0x35e5>;
                        xlnx,sat-12-desc = "Clocking , column , satellite";
                        xlnx,sat-20-y = <0x9780>;
                        xlnx,sat-19-y = <0x7f56>;
                        xlnx,sat-5-desc = "VNOC , satellite";
                        xlnx,sat-24-desc = "HBM , Satellite , (left)";
                        xlnx,sat-24-x = <0x1ea8>;
                        xlnx,sat-24-y = <0x9780>;
                        xlnx,meas-21-slr-number = <0x0>;
                        xlnx,sat-64-desc = "PS , LPD , satellite";
                        xlnx,sat-2-desc = "PMC , user , ADC";
                        xlnx,sat-28-x = <0xf56>;
                        xlnx,sat-21-desc = "VNOC , satellite";
                        xlnx,sat-28-y = <0x70fe>;
                        xlnx,sat-12-x = <0x6ed4>;
                        xlnx,meas-6-slr-number = <0x0>;
                        xlnx,meas-15-slr-number = <0x0>;
                        xlnx,sat-4-x = <0x5e61>;
                        xlnx,sat-12-y = <0x650b>;
                        xlnx,sat-4-y = <0x7362>;
                        xlnx,meas-10-slr-number = <0x0>;
                        xlnx,meas-1-slr-number = <0x0>;
                        xlnx,sat-17-desc = "VNOC , satellite";
                        xlnx,sat-16-x = <0x49e0>;
                        xlnx,sat-8-x = <0x6ed4>;
                        xlnx,sat-16-y = <0x9780>;
                        xlnx,sat-8-y = <0x7cf2>;
                        xlnx,meas-0 = "VCCAUX";
                        xlnx,meas-10 = "VCC_PSFP";
                        xlnx,meas-1 = "VCCAUX_SMON";
                        xlnx,sat-21-x = <0x21a7>;
                        xlnx,meas-11 = "VCC_PSLP";
                        xlnx,meas-2 = "VCCINT";
                        xlnx,sat-21-y = <0x676f>;
                        xlnx,sat-14-desc = "VNOC , satellite";
                        xlnx,meas-3 = "VCC_RAM";
                        xlnx,meas-12 = "VCCO_700";
                        xlnx,meas-4 = "VCC_SOC";
                        xlnx,meas-13 = "VCCO_701";
                        xlnx,sat-7-desc = "Clocking , column , satellite";
                        xlnx,meas-9-slr-number = <0x0>;
                        xlnx,meas-5 = "VCCAUX_PMC";
                        xlnx,meas-14 = "VCCO_702";
                        xlnx,meas-18-slr-number = <0x0>;
                        xlnx,sat-26-desc = "Clocking , column , satellite";
                        xlnx,sat-25-x = <0xf56>;
                        xlnx,meas-6 = "VCCO_500";
                        xlnx,meas-15 = "GTYP_AVCCAUX_104";
                        xlnx,sat-25-y = <0x8321>;
                        xlnx,meas-7 = "VCCO_501";
                        xlnx,meas-16 = "GTYP_AVCCAUX_105";
                        xlnx,sat-63-x = <0x56b>;
                        xlnx,sat-1-x = <0x56b>;
                        xlnx,sat-11-desc = "Clocking , column , satellite";
                        xlnx,meas-8 = "VCCO_503";
                        xlnx,meas-4-slr-number = <0x0>;
                        xlnx,meas-13-slr-number = <0x0>;
                        xlnx,meas-17 = "GTYP_AVCC_104";
                        xlnx,sat-63-y = <0xf11>;
                        xlnx,sat-1-y = <0x649d>;
                        xlnx,meas-9 = "VCC_PMC";
                        xlnx,meas-18 = "GTYP_AVCC_105";
                        xlnx,sat-4-desc = "VNOC , satellite";
                        xlnx,meas-19 = "GTYP_AVTT_104";
                        xlnx,meas-20 = "GTYP_AVTT_105";
                        xlnx,sat-23-desc = "VNOC , satellite";
                        xlnx,sat-13-x = <0x4a23>;
                        xlnx,meas-21 = "VCCO_502";
                        xlnx,sat-5-x = <0x5e61>;
                        xlnx,sat-13-y = <0x676f>;
                        xlnx,sat-5-y = <0x7f56>;

                        supply@6 {
                                reg = <0x6>;
                                xlnx,name = "vccaux";
                        };

                        supply@8 {
                                reg = <0x8>;
                                xlnx,name = "vccaux_smon";
                        };

                        supply@5 {
                                reg = <0x5>;
                                xlnx,name = "vccint";
                        };

                        supply@3 {
                                reg = <0x3>;
                                xlnx,name = "vcc_ram";
                        };

                        supply@4 {
                                reg = <0x4>;
                                xlnx,name = "vcc_soc";
                        };

                        supply@7 {
                                reg = <0x7>;
                                xlnx,name = "vccaux_pmc";
                        };

                        supply@9 {
                                reg = <0x9>;
                                xlnx,name = "vcco_500";
                        };

                        supply@10 {
                                reg = <0xa>;
                                xlnx,name = "vcco_501";
                        };

                        supply@12 {
                                reg = <0xc>;
                                xlnx,name = "vcco_503";
                        };

                        supply@0 {
                                reg = <0x0>;
                                xlnx,name = "vcc_pmc";
                        };

                        supply@1 {
                                reg = <0x1>;
                                xlnx,name = "vcc_psfp";
                        };

                        supply@2 {
                                reg = <0x2>;
                                xlnx,name = "vcc_pslp";
                        };

                        supply@13 {
                                reg = <0xd>;
                                xlnx,name = "vcco_700";
                        };

                        supply@14 {
                                reg = <0xe>;
                                xlnx,name = "vcco_701";
                        };

                        supply@15 {
                                reg = <0xf>;
                                xlnx,name = "vcco_702";
                        };

                        supply@20 {
                                reg = <0x14>;
                                xlnx,name = "gtyp_avccaux_104";
                        };

                        supply@21 {
                                reg = <0x15>;
                                xlnx,name = "gtyp_avccaux_105";
                        };

                        supply@18 {
                                reg = <0x12>;
                                xlnx,name = "gtyp_avcc_104";
                        };

                        supply@19 {
                                reg = <0x13>;
                                xlnx,name = "gtyp_avcc_105";
                        };

                        supply@22 {
                                reg = <0x16>;
                                xlnx,name = "gtyp_avtt_104";
                        };

                        supply@23 {
                                reg = <0x17>;
                                xlnx,name = "gtyp_avtt_105";
                        };

                        supply@11 {
                                reg = <0xb>;
                                xlnx,name = "vcco_502";
                        };
                };

                sysmon1: sysmon@109270000 {
                        phandle = <0xe4>;
                        compatible = "xlnx,versal-sysmon";
                        status = "disabled";
                        #io-channel-cells = <0x1>;
                        reg = <0x1 0x9270000 0x0 0x4000>;
                        xlnx,numchannels = [00];
                        #address-cells = <0x1>;
                        #size-cells = <0x0>;
                        xlnx,nodeid = <0x18225055>;
                };

                sysmon2: sysmon@111270000 {
                        phandle = <0xe5>;
                        compatible = "xlnx,versal-sysmon";
                        status = "disabled";
                        #io-channel-cells = <0x1>;
                        reg = <0x1 0x11270000 0x0 0x4000>;
                        xlnx,numchannels = [00];
                        #address-cells = <0x1>;
                        #size-cells = <0x0>;
                        xlnx,nodeid = <0x18226055>;
                };

                sysmon3: sysmon@119270000 {
                        phandle = <0xe6>;
                        compatible = "xlnx,versal-sysmon";
                        status = "disabled";
                        #io-channel-cells = <0x1>;
                        reg = <0x1 0x19270000 0x0 0x4000>;
                        xlnx,numchannels = [00];
                        #address-cells = <0x1>;
                        #size-cells = <0x0>;
                        xlnx,nodeid = <0x18227055>;
                };

                ttc0: timer@ff0e0000 {
                        phandle = <0x6e>;
                        compatible = "cdns,ttc";
                        status = "disabled";
                        interrupts = <0x0 0x25 0x4 0x0 0x26 0x4 0x0 0x27 0x4>;
                        interrupt-parent = <&gic>;
                        reg = <0x0 0xff0e0000 0x0 0x1000>;
                        timer-width = <0x20>;
                        clocks = <&versal_clk 0x27>;
                        power-domains = <&versal_firmware 0x18224024>;
                        xlnx,ttc-board-interface = "custom";
                        xlnx,ttc-clk2-freq-hz = <0x8f0d180>;
                        xlnx,ttc-clk1-clksrc = <0x0>;
                        xlnx,clock-freq = <0x8f0d180>;
                        xlnx,ttc-clk2-clksrc = <0x0>;
                        xlnx,ip-name = "psv_ttc";
                        xlnx,ttc-clk0-freq-hz = <0x8f0d180>;
                        xlnx,ttc-clk1-freq-hz = <0x8f0d180>;
                        xlnx,ttc-clk0-clksrc = <0x0>;
                };

                ttc1: timer@ff0f0000 {
                        phandle = <0x6f>;
                        compatible = "cdns,ttc";
                        status = "disabled";
                        interrupts = <0x0 0x28 0x4 0x0 0x29 0x4 0x0 0x2a 0x4>;
                        interrupt-parent = <&gic>;
                        reg = <0x0 0xff0f0000 0x0 0x1000>;
                        timer-width = <0x20>;
                        clocks = <&versal_clk 0x28>;
                        power-domains = <&versal_firmware 0x18224025>;
                        xlnx,ttc-board-interface = "custom";
                        xlnx,ttc-clk2-freq-hz = <0x8f0d180>;
                        xlnx,ttc-clk1-clksrc = <0x0>;
                        xlnx,clock-freq = <0x8f0d180>;
                        xlnx,ttc-clk2-clksrc = <0x0>;
                        xlnx,ip-name = "psv_ttc";
                        xlnx,ttc-clk0-freq-hz = <0x8f0d180>;
                        xlnx,ttc-clk1-freq-hz = <0x8f0d180>;
                        xlnx,ttc-clk0-clksrc = <0x0>;
                };

                ttc2: timer@ff100000 {
                        phandle = <0x70>;
                        compatible = "cdns,ttc";
                        status = "okay";
                        interrupts = <0x0 0x2b 0x4 0x0 0x2c 0x4 0x0 0x2d 0x4>;
                        interrupt-parent = <&gic>;
                        reg = <0x0 0xff100000 0x0 0x1000>;
                        timer-width = <0x20>;
                        clocks = <&versal_clk 0x29>;
                        power-domains = <&versal_firmware 0x18224026>;
                        xlnx,ttc-board-interface = "custom";
                        xlnx,ttc-clk2-freq-hz = <0x8f0d180>;
                        xlnx,ttc-clk1-clksrc = <0x0>;
                        xlnx,clock-freq = <0x8f0d180>;
                        xlnx,ttc-clk2-clksrc = <0x0>;
                        xlnx,ip-name = "psv_ttc";
                        xlnx,ttc-clk0-freq-hz = <0x8f0d180>;
                        xlnx,ttc-clk1-freq-hz = <0x8f0d180>;
                        xlnx,ttc-clk0-clksrc = <0x0>;
                };

                ttc3: timer@ff110000 {
                        phandle = <0x71>;
                        compatible = "cdns,ttc";
                        status = "okay";
                        interrupts = <0x0 0x2e 0x4 0x0 0x2f 0x4 0x0 0x30 0x4>;
                        interrupt-parent = <&gic>;
                        reg = <0x0 0xff110000 0x0 0x1000>;
                        timer-width = <0x20>;
                        clocks = <&versal_clk 0x2a>;
                        power-domains = <&versal_firmware 0x18224027>;
                        xlnx,ttc-board-interface = "custom";
                        xlnx,ttc-clk2-freq-hz = <0x8f0d180>;
                        xlnx,ttc-clk1-clksrc = <0x0>;
                        xlnx,clock-freq = <0x8f0d180>;
                        xlnx,ttc-clk2-clksrc = <0x0>;
                        xlnx,ip-name = "psv_ttc";
                        xlnx,ttc-clk0-freq-hz = <0x8f0d180>;
                        xlnx,ttc-clk1-freq-hz = <0x8f0d180>;
                        xlnx,ttc-clk0-clksrc = <0x0>;
                };

                usb0: usb@ff9d0000 {
                        phandle = <0xe7>;
                        compatible = "xlnx,versal-dwc3";
                        status = "disabled";
                        reg = <0x0 0xff9d0000 0x0 0x100>;
                        clock-names = "bus_clk", "ref_clk";
                        ranges;
                        #address-cells = <0x2>;
                        #size-cells = <0x2>;
                        clocks = <&versal_clk 0x5b>,
                         <&versal_clk 0x68>;
                        power-domains = <&versal_firmware 0x18224018>;
                        resets = <&versal_reset 0xc104036>;

                        dwc3_0: usb@fe200000 {
                                phandle = <0xe8>;
                                compatible = "snps,dwc3";
                                status = "disabled";
                                reg = <0x0 0xfe200000 0x0 0x10000>;
                                interrupt-names = "host", "peripheral", "otg", "wakeup";
                                interrupts = <0x0 0x16 0x4 0x0 0x16 0x4 0x0 0x1a 0x4 0x0 0x4a 0x4>;
                                interrupt-parent = <&gic>;
                                snps,dis_u2_susphy_quirk;
                                snps,dis_u3_susphy_quirk;
                                snps,quirk-frame-length-adjustment = <0x20>;
                                clock-names = "ref";
                                clocks = <&versal_clk 0x5b>;
                        };
                };

                cpm_pciea: pci@fca10000 {
                        phandle = <0xe9>;
                        device_type = "pci";
                        #address-cells = <0x3>;
                        #interrupt-cells = <0x1>;
                        #size-cells = <0x2>;
                        compatible = "xlnx,versal-cpm-host-1.00";
                        status = "disabled";
                        interrupt-map = <0x0 0x0 0x0 0x1 &pcie_intc_0 0x0>,
                         <0x0 0x0 0x0 0x2 &pcie_intc_0 0x1>,
                         <0x0 0x0 0x0 0x3 &pcie_intc_0 0x2>,
                         <0x0 0x0 0x0 0x4 &pcie_intc_0 0x3>;
                        interrupt-map-mask = <0x0 0x0 0x0 0x7>;
                        interrupt-names = "misc";
                        interrupts = <0x0 0x48 0x4>;
                        xlnx,csr-slcr = <0x6 0x0>;
                        xlnx,num-of-bars = <0x2>;
                        xlnx,port-type = <0x1>;
                        interrupt-parent = <&gic>;
                        bus-range = <0x0 0xff>;
                        ranges = <0x2000000 0x0 0xe0010000 0x0 0xe0010000 0x0 0x10000000 0x43000000 0x80 0x0 0x80 0x0 0x0 0x80000000>;
                        msi-map = <0x0 &gic_its 0x0 0x10000>;
                        reg = <0x6 0x0 0x0 0x10000000 0x0 0xfca10000 0x0 0x1000 0x0 0xfca00000 0x0 0x10000>;
                        reg-names = "cfg", "cpm_slcr", "cpm_crx";

                        pcie_intc_0: interrupt-controller {
                                phandle = <0xaf>;
                                #address-cells = <0x0>;
                                #interrupt-cells = <0x1>;
                                interrupt-controller;
                        };
                };

                cpm5_pcie: pcie@fcdd0000 {
                        phandle = <0xea>;
                        device_type = "pci";
                        #address-cells = <0x3>;
                        #interrupt-cells = <0x1>;
                        #size-cells = <0x2>;
                        compatible = "xlnx,versal-cpm5-host";
                        status = "disabled";
                        interrupt-map = <0x0 0x0 0x0 0x1 &pcie_intc_2 0x0>,
                         <0x0 0x0 0x0 0x2 &pcie_intc_2 0x1>,
                         <0x0 0x0 0x0 0x3 &pcie_intc_2 0x2>,
                         <0x0 0x0 0x0 0x4 &pcie_intc_2 0x3>;
                        interrupt-map-mask = <0x0 0x0 0x0 0x7>;
                        interrupt-names = "misc";
                        interrupts = <0x0 0x48 0x4>;
                        xlnx,csr-slcr = <0xfce20000>;
                        xlnx,num-of-bars = <0x2>;
                        xlnx,port-type = <0x1>;
                        interrupt-parent = <&gic>;
                        bus-range = <0x0 0xff>;
                        ranges = <0x2000000 0x0 0xe0000000 0x0 0xe0000000 0x0 0x10000000 0x43000000 0x80 0x0 0x80 0x0 0x0 0x80000000>;
                        msi-map = <0x0 &gic_its 0x0 0x10000>;
                        reg = <0x6 0x0 0x0 0x10000000 0x0 0xfcdd0000 0x0 0x1000 0x0 0xfce20000 0x0 0x10000 0x0 0xfcdc0000 0x0 0x10000>;
                        reg-names = "cfg", "cpm_slcr", "cpm_csr", "cpm_crx";

                        pcie_intc_2: interrupt-controller {
                                phandle = <0xb0>;
                                #address-cells = <0x0>;
                                #interrupt-cells = <0x1>;
                                interrupt-controller;
                        };
                };

                watchdog: watchdog@fd4d0000 {
                        phandle = <0xeb>;
                        compatible = "xlnx,versal-wwdt";
                        status = "disabled";
                        reg = <0x0 0xfd4d0000 0x0 0x10000>;
                        interrupt-names = "wdt", "wwdt_reset_pending", "gwdt", "gwdt_reset_pending";
                        interrupts = <0x0 0x64 0x1 0x0 0x6d 0x1 0x0 0x6c 0x1 0x0 0x6e 0x1>;
                        interrupt-parent = <&gic>;
                        timeout-sec = <0x1e>;
                        clocks = <&versal_clk 0x4c>;
                        power-domains = <&versal_firmware 0x18224029>;
                };

                watchdog1: watchdog@ff120000 {
                        phandle = <0xec>;
                        compatible = "xlnx,versal-wwdt";
                        status = "disabled";
                        reg = <0x0 0xff120000 0x0 0x10000>;
                        interrupt-parent = <&gic>;
                        interrupt-names = "wdt", "wwdt_reset_pending", "gwdt", "gwdt_reset_pending";
                        interrupts = <0x0 0x31 0x1 0x0 0x45 0x1 0x0 0x46 0x4 0x0 0x47 0x4>;
                        timeout-sec = <0x1e>;
                        clocks = <&versal_clk 0x52>;
                        power-domains = <&versal_firmware 0x18224028>;
                };

                xilsem_edac: edac@f2014050 {
                        phandle = <0xed>;
                        compatible = "xlnx,versal-xilsem-edac";
                        status = "disabled";
                        reg = <0x0 0xf2014050 0x0 0xc4>;
                };

                dma0: pmcdma@f11c0000 {
                        phandle = <0x35>;
                        status = "okay";
                        compatible = "xlnx,zynqmp-csudma-1.0";
                        interrupt-parent = <&gic>;
                        interrupts = <0x0 0x83 0x4>;
                        reg = <0x0 0xf11c0000 0x0 0x10000>;
                        xlnx,dma-type = <0x1>;
                        xlnx,ip-name = "psv_pmc_dma";
                };

                dma1: pmcdma@f11d0000 {
                        phandle = <0x36>;
                        status = "okay";
                        compatible = "xlnx,zynqmp-csudma-1.0";
                        interrupt-parent = <&gic>;
                        interrupts = <0x0 0x84 0x4>;
                        reg = <0x0 0xf11d0000 0x0 0x10000>;
                        xlnx,dma-type = <0x2>;
                        xlnx,ip-name = "psv_pmc_dma";
                };

                ipi0: mailbox@ff330000 {
                        phandle = <0x7>;
                        compatible = "xlnx,versal-ipi-mailbox";
                        interrupt-parent = <&gic>;
                        interrupts = <0x0 0x1e 0x4>;
                        reg = <0x0 0xff330000 0x0 0x10000 0x0 0xff3f0400 0x0 0x200>;
                        xlnx,ipi-id = <0x2>;
                        #address-cells = <0x2>;
                        #size-cells = <0x2>;
                        ranges;
                        reg-names = "ctrl", "msg";

                        ipi_0_to_ipi_0: child@ff330000 {
                                phandle = <0x10c>;
                                compatible = "xlnx,versal-ipi-dest-mailbox";
                                #mbox-cells = <0x1>;
                                xlnx,ipi-id = <0x2>;
                                reg = <0x0 0xff330000 0x0 0x10000 0x0 0xff3f0400 0x0 0x200>;
                                reg-names = "ctrl", "msg";
                        };

                        ipi_0_to_ipi_1: child@ff340000 {
                                phandle = <0x10d>;
                                compatible = "xlnx,versal-ipi-dest-mailbox";
                                #mbox-cells = <0x1>;
                                xlnx,ipi-id = <0x3>;
                                reg = <0x0 0xff340000 0x0 0x10000 0x0 0xff3f0600 0x0 0x200>;
                                reg-names = "ctrl", "msg";
                        };

                        ipi_0_to_ipi_2: child@ff350000 {
                                phandle = <0x10e>;
                                compatible = "xlnx,versal-ipi-dest-mailbox";
                                #mbox-cells = <0x1>;
                                xlnx,ipi-id = <0x4>;
                                reg = <0x0 0xff350000 0x0 0x10000 0x0 0xff3f0800 0x0 0x200>;
                                reg-names = "ctrl", "msg";
                        };

                        ipi_0_to_ipi_3: child@ff360000 {
                                phandle = <0x10f>;
                                compatible = "xlnx,versal-ipi-dest-mailbox";
                                #mbox-cells = <0x1>;
                                xlnx,ipi-id = <0x5>;
                                reg = <0x0 0xff360000 0x0 0x10000 0x0 0xff3f0a00 0x0 0x200>;
                                reg-names = "ctrl", "msg";
                        };

                        ipi_0_to_ipi_4: child@ff370000 {
                                phandle = <0x110>;
                                compatible = "xlnx,versal-ipi-dest-mailbox";
                                #mbox-cells = <0x1>;
                                xlnx,ipi-id = <0x6>;
                                reg = <0x0 0xff370000 0x0 0x10000 0x0 0xff3f0c00 0x0 0x200>;
                                reg-names = "ctrl", "msg";
                        };

                        ipi_0_to_ipi_5: child@ff380000 {
                                phandle = <0x111>;
                                compatible = "xlnx,versal-ipi-dest-mailbox";
                                #mbox-cells = <0x1>;
                                xlnx,ipi-id = <0x7>;
                                reg = <0x0 0xff380000 0x0 0x10000 0x0 0xff3f0e00 0x0 0x200>;
                                reg-names = "ctrl", "msg";
                        };

                        ipi_0_to_ipi_6: child@ff3a0000 {
                                phandle = <0x112>;
                                compatible = "xlnx,versal-ipi-dest-mailbox";
                                #mbox-cells = <0x1>;
                                xlnx,ipi-id = <0x9>;
                                reg = <0x0 0xff3a0000 0x0 0x10000>;
                                reg-names = "ctrl";
                        };

                        ipi_0_to_ipi_pmc: child@ff320000 {
                                phandle = <0x113>;
                                compatible = "xlnx,versal-ipi-dest-mailbox";
                                #mbox-cells = <0x1>;
                                xlnx,ipi-id = <0x1>;
                                reg = <0x0 0xff320000 0x0 0x10000 0x0 0xff3f0200 0x0 0x200>;
                                reg-names = "ctrl", "msg";
                        };

                        ipi_0_to_ipi_pmc_nobuf: child@ff390000 {
                                phandle = <0x114>;
                                compatible = "xlnx,versal-ipi-dest-mailbox";
                                #mbox-cells = <0x1>;
                                xlnx,ipi-id = <0x8>;
                                reg = <0x0 0xff390000 0x0 0x10000>;
                                reg-names = "ctrl";
                        };

                        ipi_0_to_ipi_psm: child@ff310000 {
                                phandle = <0x115>;
                                compatible = "xlnx,versal-ipi-dest-mailbox";
                                #mbox-cells = <0x1>;
                                xlnx,ipi-id = <0x0>;
                                reg = <0x0 0xff310000 0x0 0x10000 0x0 0xff3f0000 0x0 0x200>;
                                reg-names = "ctrl", "msg";
                        };
                };

                ipi1: mailbox@ff340000 {
                        phandle = <0x8>;
                        compatible = "xlnx,versal-ipi-mailbox";
                        interrupt-parent = <&gic>;
                        interrupts = <0x0 0x1f 0x4>;
                        reg = <0x0 0xff340000 0x0 0x10000 0x0 0xff3f0600 0x0 0x200>;
                        xlnx,ipi-id = <0x3>;
                        #address-cells = <0x2>;
                        #size-cells = <0x2>;
                        ranges;
                        reg-names = "ctrl", "msg";

                        ipi_1_to_ipi_0: child@ff330000 {
                                phandle = <0x116>;
                                compatible = "xlnx,versal-ipi-dest-mailbox";
                                #mbox-cells = <0x1>;
                                xlnx,ipi-id = <0x2>;
                                reg = <0x0 0xff330000 0x0 0x10000 0x0 0xff3f0400 0x0 0x200>;
                                reg-names = "ctrl", "msg";
                        };

                        ipi_1_to_ipi_1: child@ff340000 {
                                phandle = <0x117>;
                                compatible = "xlnx,versal-ipi-dest-mailbox";
                                #mbox-cells = <0x1>;
                                xlnx,ipi-id = <0x3>;
                                reg = <0x0 0xff340000 0x0 0x10000 0x0 0xff3f0600 0x0 0x200>;
                                reg-names = "ctrl", "msg";
                        };

                        ipi_1_to_ipi_2: child@ff350000 {
                                phandle = <0x118>;
                                compatible = "xlnx,versal-ipi-dest-mailbox";
                                #mbox-cells = <0x1>;
                                xlnx,ipi-id = <0x4>;
                                reg = <0x0 0xff350000 0x0 0x10000 0x0 0xff3f0800 0x0 0x200>;
                                reg-names = "ctrl", "msg";
                        };

                        ipi_1_to_ipi_3: child@ff360000 {
                                phandle = <0x119>;
                                compatible = "xlnx,versal-ipi-dest-mailbox";
                                #mbox-cells = <0x1>;
                                xlnx,ipi-id = <0x5>;
                                reg = <0x0 0xff360000 0x0 0x10000 0x0 0xff3f0a00 0x0 0x200>;
                                reg-names = "ctrl", "msg";
                        };

                        ipi_1_to_ipi_4: child@ff370000 {
                                phandle = <0x11a>;
                                compatible = "xlnx,versal-ipi-dest-mailbox";
                                #mbox-cells = <0x1>;
                                xlnx,ipi-id = <0x6>;
                                reg = <0x0 0xff370000 0x0 0x10000 0x0 0xff3f0c00 0x0 0x200>;
                                reg-names = "ctrl", "msg";
                        };

                        ipi_1_to_ipi_5: child@ff380000 {
                                phandle = <0x11b>;
                                compatible = "xlnx,versal-ipi-dest-mailbox";
                                #mbox-cells = <0x1>;
                                xlnx,ipi-id = <0x7>;
                                reg = <0x0 0xff380000 0x0 0x10000 0x0 0xff3f0e00 0x0 0x200>;
                                reg-names = "ctrl", "msg";
                        };

                        ipi_1_to_ipi_6: child@ff3a0000 {
                                phandle = <0x11c>;
                                compatible = "xlnx,versal-ipi-dest-mailbox";
                                #mbox-cells = <0x1>;
                                xlnx,ipi-id = <0x9>;
                                reg = <0x0 0xff3a0000 0x0 0x10000>;
                                reg-names = "ctrl";
                        };

                        ipi_1_to_ipi_pmc: child@ff320000 {
                                phandle = <0x11d>;
                                compatible = "xlnx,versal-ipi-dest-mailbox";
                                #mbox-cells = <0x1>;
                                xlnx,ipi-id = <0x1>;
                                reg = <0x0 0xff320000 0x0 0x10000 0x0 0xff3f0200 0x0 0x200>;
                                reg-names = "ctrl", "msg";
                        };

                        ipi_1_to_ipi_pmc_nobuf: child@ff390000 {
                                phandle = <0x11e>;
                                compatible = "xlnx,versal-ipi-dest-mailbox";
                                #mbox-cells = <0x1>;
                                xlnx,ipi-id = <0x8>;
                                reg = <0x0 0xff390000 0x0 0x10000>;
                                reg-names = "ctrl";
                        };

                        ipi_1_to_ipi_psm: child@ff310000 {
                                phandle = <0x11f>;
                                compatible = "xlnx,versal-ipi-dest-mailbox";
                                #mbox-cells = <0x1>;
                                xlnx,ipi-id = <0x0>;
                                reg = <0x0 0xff310000 0x0 0x10000 0x0 0xff3f0000 0x0 0x200>;
                                reg-names = "ctrl", "msg";
                        };
                };

                ipi2: mailbox@ff350000 {
                        phandle = <0x9>;
                        compatible = "xlnx,versal-ipi-mailbox";
                        interrupt-parent = <&gic>;
                        interrupts = <0x0 0x20 0x4>;
                        reg = <0x0 0xff350000 0x0 0x10000 0x0 0xff3f0800 0x0 0x200>;
                        xlnx,ipi-id = <0x4>;
                        #address-cells = <0x2>;
                        #size-cells = <0x2>;
                        ranges;
                        reg-names = "ctrl", "msg";

                        ipi_2_to_ipi_0: child@ff330000 {
                                phandle = <0x120>;
                                compatible = "xlnx,versal-ipi-dest-mailbox";
                                #mbox-cells = <0x1>;
                                xlnx,ipi-id = <0x2>;
                                reg = <0x0 0xff330000 0x0 0x10000 0x0 0xff3f0400 0x0 0x200>;
                                reg-names = "ctrl", "msg";
                        };

                        ipi_2_to_ipi_1: child@ff340000 {
                                phandle = <0x121>;
                                compatible = "xlnx,versal-ipi-dest-mailbox";
                                #mbox-cells = <0x1>;
                                xlnx,ipi-id = <0x3>;
                                reg = <0x0 0xff340000 0x0 0x10000 0x0 0xff3f0600 0x0 0x200>;
                                reg-names = "ctrl", "msg";
                        };

                        ipi_2_to_ipi_2: child@ff350000 {
                                phandle = <0x122>;
                                compatible = "xlnx,versal-ipi-dest-mailbox";
                                #mbox-cells = <0x1>;
                                xlnx,ipi-id = <0x4>;
                                reg = <0x0 0xff350000 0x0 0x10000 0x0 0xff3f0800 0x0 0x200>;
                                reg-names = "ctrl", "msg";
                        };

                        ipi_2_to_ipi_3: child@ff360000 {
                                phandle = <0x123>;
                                compatible = "xlnx,versal-ipi-dest-mailbox";
                                #mbox-cells = <0x1>;
                                xlnx,ipi-id = <0x5>;
                                reg = <0x0 0xff360000 0x0 0x10000 0x0 0xff3f0a00 0x0 0x200>;
                                reg-names = "ctrl", "msg";
                        };

                        ipi_2_to_ipi_4: child@ff370000 {
                                phandle = <0x124>;
                                compatible = "xlnx,versal-ipi-dest-mailbox";
                                #mbox-cells = <0x1>;
                                xlnx,ipi-id = <0x6>;
                                reg = <0x0 0xff370000 0x0 0x10000 0x0 0xff3f0c00 0x0 0x200>;
                                reg-names = "ctrl", "msg";
                        };

                        ipi_2_to_ipi_5: child@ff380000 {
                                phandle = <0x125>;
                                compatible = "xlnx,versal-ipi-dest-mailbox";
                                #mbox-cells = <0x1>;
                                xlnx,ipi-id = <0x7>;
                                reg = <0x0 0xff380000 0x0 0x10000 0x0 0xff3f0e00 0x0 0x200>;
                                reg-names = "ctrl", "msg";
                        };

                        ipi_2_to_ipi_6: child@ff3a0000 {
                                phandle = <0x126>;
                                compatible = "xlnx,versal-ipi-dest-mailbox";
                                #mbox-cells = <0x1>;
                                xlnx,ipi-id = <0x9>;
                                reg = <0x0 0xff3a0000 0x0 0x10000>;
                                reg-names = "ctrl";
                        };

                        ipi_2_to_ipi_pmc: child@ff320000 {
                                phandle = <0x127>;
                                compatible = "xlnx,versal-ipi-dest-mailbox";
                                #mbox-cells = <0x1>;
                                xlnx,ipi-id = <0x1>;
                                reg = <0x0 0xff320000 0x0 0x10000 0x0 0xff3f0200 0x0 0x200>;
                                reg-names = "ctrl", "msg";
                        };

                        ipi_2_to_ipi_pmc_nobuf: child@ff390000 {
                                phandle = <0x128>;
                                compatible = "xlnx,versal-ipi-dest-mailbox";
                                #mbox-cells = <0x1>;
                                xlnx,ipi-id = <0x8>;
                                reg = <0x0 0xff390000 0x0 0x10000>;
                                reg-names = "ctrl";
                        };

                        ipi_2_to_ipi_psm: child@ff310000 {
                                phandle = <0x129>;
                                compatible = "xlnx,versal-ipi-dest-mailbox";
                                #mbox-cells = <0x1>;
                                xlnx,ipi-id = <0x0>;
                                reg = <0x0 0xff310000 0x0 0x10000 0x0 0xff3f0000 0x0 0x200>;
                                reg-names = "ctrl", "msg";
                        };
                };

                coresight: coresight@f0800000 {
                        phandle = <0xe>;
                        compatible = "xlnx,coresight-1.0";
                        status = "okay";
                        reg = <0x0 0xf0800000 0x0 0x10000>;
                        xlnx,ip-name = "psv_coresight";
                };

                cips_pspmc_0_psv_coresight_fpd_cti1b: cips_pspmc_0_psv_coresight_fpd_cti1b@f0bb0000 {
                        phandle = <0x16>;
                        compatible = "xlnx,psv-coresight-fpd-cti1b-1.0";
                        status = "okay";
                        xlnx,ip-name = "psv_coresight_fpd_cti1b";
                        reg = <0x0 0xf0bb0000 0x0 0x10000>;
                };

                cips_pspmc_0_psv_coresight_fpd_cti1c: cips_pspmc_0_psv_coresight_fpd_cti1c@f0bc0000 {
                        phandle = <0x17>;
                        compatible = "xlnx,psv-coresight-fpd-cti1c-1.0";
                        status = "okay";
                        xlnx,ip-name = "psv_coresight_fpd_cti1c";
                        reg = <0x0 0xf0bc0000 0x0 0x10000>;
                };

                cips_pspmc_0_psv_coresight_fpd_cti1d: cips_pspmc_0_psv_coresight_fpd_cti1d@f0bd0000 {
                        phandle = <0x18>;
                        compatible = "xlnx,psv-coresight-fpd-cti1d-1.0";
                        status = "okay";
                        xlnx,ip-name = "psv_coresight_fpd_cti1d";
                        reg = <0x0 0xf0bd0000 0x0 0x10000>;
                };

                cips_pspmc_0_psv_coresight_lpd_cti: cips_pspmc_0_psv_coresight_lpd_cti@f09d0000 {
                        phandle = <0x11>;
                        compatible = "xlnx,psv-coresight-lpd-cti-1.0";
                        status = "okay";
                        xlnx,ip-name = "psv_coresight_lpd_cti";
                        reg = <0x0 0xf09d0000 0x0 0x10000>;
                };

                cips_pspmc_0_psv_coresight_pmc_cti: cips_pspmc_0_psv_coresight_pmc_cti@f08d0000 {
                        phandle = <0xf>;
                        compatible = "xlnx,psv-coresight-pmc-cti-1.0";
                        status = "okay";
                        xlnx,ip-name = "psv_coresight_pmc_cti";
                        reg = <0x0 0xf08d0000 0x0 0x10000>;
                };

                cips_pspmc_0_psv_coresight_r50_cti: cips_pspmc_0_psv_coresight_r50_cti@f0a10000 {
                        phandle = <0x12>;
                        compatible = "xlnx,psv-coresight-r50-cti-1.0";
                        status = "okay";
                        xlnx,ip-name = "psv_coresight_r50_cti";
                        reg = <0x0 0xf0a10000 0x0 0x10000>;
                };

                cips_pspmc_0_psv_coresight_r51_cti: cips_pspmc_0_psv_coresight_r51_cti@f0a50000 {
                        phandle = <0x13>;
                        compatible = "xlnx,psv-coresight-r51-cti-1.0";
                        status = "okay";
                        xlnx,ip-name = "psv_coresight_r51_cti";
                        reg = <0x0 0xf0a50000 0x0 0x10000>;
                };

                cips_pspmc_0_psv_cpm: cips_pspmc_0_psv_cpm@0 {
                        phandle = <0x59>;
                        compatible = "xlnx,psv-cpm-1.0";
                        status = "okay";
                        xlnx,ip-name = "psv_cpm";
                        reg = <0x0 0xfc000000 0x0 0x1000000>;
                };

                cips_pspmc_0_psv_pmc_analog_0: cips_pspmc_0_psv_pmc_analog_0@f1160000 {
                        phandle = <0x33>;
                        compatible = "xlnx,psv-pmc-analog-1.0";
                        status = "okay";
                        xlnx,ip-name = "psv_pmc_analog";
                        reg = <0x0 0xf1160000 0x0 0x30000>;
                        xlnx,npi-scan = <0x0>;
                        xlnx,event-log = <0x0>;
                        xlnx,cram-scan = <0x0>;
                };

                cips_pspmc_0_psv_pmc_iou_slcr_0: cips_pspmc_0_psv_pmc_iou_slcr_0@f1060000 {
                        phandle = <0x31>;
                        compatible = "xlnx,psv-pmc-iou-slcr-1.0";
                        status = "okay";
                        xlnx,ip-name = "psv_pmc_iou_slcr";
                        reg = <0x0 0xf1060000 0x0 0x10000>;
                };

                cips_pspmc_0_psv_pmc_tap: cips_pspmc_0_psv_pmc_tap@f11a0000 {
                        phandle = <0x34>;
                        compatible = "xlnx,psv-pmc-tap-1.0";
                        status = "okay";
                        xlnx,ip-name = "psv_pmc_tap";
                        reg = <0x0 0xf11a0000 0x0 0x20000>;
                };

                gic: interrupt-controller@f9000000 {
                        phandle = <0x58>;
                        xlnx,ip-name = "psv_acpu_gic";
                        xlnx,apu-gic-its-ctl = <0xf9020000>;
                        status = "okay";
                        interrupts = <0x1 0x9 0x4>;
                        interrupt-parent = <&gic>;
                        interrupt-controller;
                        reg = <0x0 0xf9000000 0x0 0x80000 0x0 0xf9080000 0x0 0x80000>;
                        ranges;
                        #size-cells = <0x2>;
                        #address-cells = <0x2>;
                        #interrupt-cells = <0x3>;
                        compatible = "arm,gic-v3";

                        gic_its: msi-controller@f9020000 {
                                phandle = <0x6>;
                                reg = <0x0 0xf9020000 0x0 0x20000>;
                                #msi-cells = <0x1>;
                                msi-controller;
                                status = "okay";
                                compatible = "arm,gic-v3-its";
                        };
                };
        };

        amba_xppu: indirect-bus@1 {
                phandle = <0x15f>;
                compatible = "indirect-bus";
                #address-cells = <0x2>;
                #size-cells = <0x2>;

                lpd_xppu: xppu@ff990000 {
                        phandle = <0x79>;
                        compatible = "xlnx,xppu";
                        #firewall-cells = <0x0>;
                        reg = <0x0 0xff990000 0x0 0x2000>;
                        status = "okay";
                        xlnx,ip-name = "psv_lpd_xppu";
                };

                pmc_xppu: xppu@f1310000 {
                        phandle = <0x55>;
                        compatible = "xlnx,xppu";
                        #firewall-cells = <0x0>;
                        reg = <0x0 0xf1310000 0x0 0x2000>;
                        status = "okay";
                        xlnx,ip-name = "psv_pmc_xppu";
                };

                pmc_xppu_npi: xppu@f1300000 {
                        phandle = <0x54>;
                        compatible = "xlnx,xppu";
                        #firewall-cells = <0x0>;
                        reg = <0x0 0xf1300000 0x0 0x2000>;
                        status = "okay";
                        xlnx,ip-name = "psv_pmc_xppu_npi";
                };
        };

        amba_xmpu: indirect-bus@2 {
                phandle = <0x160>;
                compatible = "indirect-bus";
                #address-cells = <0x2>;
                #size-cells = <0x2>;

                fpd_xmpu: xmpu@fd390000 {
                        phandle = <0x5e>;
                        compatible = "xlnx,xmpu";
                        #firewall-cells = <0x0>;
                        reg = <0x0 0xfd390000 0x0 0x1000>;
                        status = "okay";
                        xlnx,ip-name = "psv_fpd_slave_xmpu";
                };

                pmc_xmpu: xmpu@f12f0000 {
                        phandle = <0x53>;
                        compatible = "xlnx,xmpu";
                        #firewall-cells = <0x0>;
                        reg = <0x0 0xf12f0000 0x0 0x1000>;
                        status = "okay";
                        xlnx,ip-name = "psv_pmc_xmpu";
                };

                ocm_xmpu: xmpu@ff980000 {
                        phandle = <0x78>;
                        compatible = "xlnx,xmpu";
                        #firewall-cells = <0x0>;
                        reg = <0x0 0xff980000 0x0 0x1000>;
                        status = "okay";
                        xlnx,ip-name = "psv_ocm_xmpu";
                };

                ddrmc_xmpu_0: xmpu@f6080000 {
                        phandle = <0x161>;
                        compatible = "xlnx,xmpu";
                        #firewall-cells = <0x0>;
                        reg = <0x0 0xf6080000 0x0 0x1000>;
                        status = "disabled";
                };

                ddrmc_xmpu_1: xmpu@f6220000 {
                        phandle = <0x162>;
                        compatible = "xlnx,xmpu";
                        #firewall-cells = <0x0>;
                        reg = <0x0 0xf6220000 0x0 0x1000>;
                        status = "disabled";
                };

                ddrmc_xmpu_2: xmpu@f6390000 {
                        phandle = <0x163>;
                        compatible = "xlnx,xmpu";
                        #firewall-cells = <0x0>;
                        reg = <0x0 0xf6390000 0x0 0x1000>;
                        status = "disabled";
                };

                ddrmc_xmpu_3: xmpu@f6500000 {
                        phandle = <0x164>;
                        compatible = "xlnx,xmpu";
                        #firewall-cells = <0x0>;
                        reg = <0x0 0xf6500000 0x0 0x1000>;
                        status = "disabled";
                };

                fpd_funnel: fpd-funnel@f0b20000 {
                        phandle = <0x165>;
                        compatible = "arm,coresight-dynamic-funnel", "arm,primecell";
                        reg = <0x0 0xf0b20000 0x0 0x1000>;
                        clock-names = "apb_pclk";
                        status = "disabled";
                        clocks = <&versal_clk 0x52>;

                        in-ports {
                                #address-cells = <0x1>;
                                #size-cells = <0x0>;

                                port@1 {
                                        reg = <0x1>;

                                        fpd_funnel_in_port1: endpoint {
                                                phandle = <0xbc>;
                                                remote-endpoint = <&apu_etf_out_port>;
                                        };
                                };
                        };

                        out-ports {

                                port {

                                        fpd_funnel_out_port: endpoint {
                                                phandle = <0xb3>;
                                                remote-endpoint = <&fpd_etf_in_port>;
                                        };
                                };
                        };
                };

                fpd_etf: fpd-etf@f0b30000 {
                        phandle = <0x166>;
                        compatible = "arm,coresight-tmc", "arm,primecell";
                        reg = <0x0 0xf0b30000 0x0 0x1000>;
                        clock-names = "apb_pclk";
                        status = "disabled";
                        clocks = <&versal_clk 0x52>;

                        in-ports {

                                port {

                                        fpd_etf_in_port: endpoint {
                                                phandle = <0xb2>;
                                                remote-endpoint = <&fpd_funnel_out_port>;
                                        };
                                };
                        };

                        out-ports {

                                port {

                                        fpd_etf_out_port: endpoint {
                                                phandle = <0xb5>;
                                                remote-endpoint = <&replicator_in_port>;
                                        };
                                };
                        };
                };

                replicator: replicator@f0b40000 {
                        phandle = <0x167>;
                        compatible = "arm,coresight-dynamic-replicator", "arm,primecell";
                        reg = <0x0 0xf0b40000 0x0 0x1000>;
                        clock-names = "apb_pclk";
                        status = "disabled";
                        clocks = <&versal_clk 0x52>;

                        in-ports {

                                port {

                                        replicator_in_port: endpoint {
                                                phandle = <0xb4>;
                                                remote-endpoint = <&fpd_etf_out_port>;
                                        };
                                };
                        };

                        out-ports {
                                #address-cells = <0x1>;
                                #size-cells = <0x0>;

                                port@0 {
                                        reg = <0x0>;

                                        replicator_out_port0: endpoint {
                                                phandle = <0xb7>;
                                                remote-endpoint = <&etr_in_port>;
                                        };
                                };
                        };
                };

                etr: etr@f0b50000 {
                        phandle = <0x168>;
                        compatible = "arm,coresight-tmc", "arm,primecell";
                        reg = <0x0 0xf0b50000 0x0 0x1000>;
                        clock-names = "apb_pclk";
                        status = "disabled";
                        clocks = <&versal_clk 0x52>;

                        in-ports {

                                port {

                                        etr_in_port: endpoint {
                                                phandle = <0xb6>;
                                                remote-endpoint = <&replicator_out_port0>;
                                        };
                                };
                        };
                };

                apu_funnel: funnel@f0c20000 {
                        phandle = <0x169>;
                        compatible = "arm,coresight-dynamic-funnel", "arm,primecell";
                        reg = <0x0 0xf0c20000 0x0 0x1000>;
                        clock-names = "apb_pclk";
                        status = "disabled";
                        clocks = <&versal_clk 0x52>;

                        in-ports {
                                #address-cells = <0x1>;
                                #size-cells = <0x0>;

                                port@0 {
                                        reg = <0x0>;

                                        funnel_in_port0: endpoint {
                                                phandle = <0xbe>;
                                                remote-endpoint = <&etm0_out_port>;
                                        };
                                };

                                port@1 {
                                        reg = <0x1>;

                                        funnel_in_port1: endpoint {
                                                phandle = <0xc0>;
                                                remote-endpoint = <&etm1_out_port>;
                                        };
                                };
                        };

                        out-ports {

                                port {

                                        funnel_out_port: endpoint {
                                                phandle = <0xbb>;
                                                remote-endpoint = <&etf_in_port>;
                                        };
                                };
                        };
                };

                apu_etf: etf@f0c30000 {
                        phandle = <0x16a>;
                        compatible = "arm,coresight-tmc", "arm,primecell";
                        reg = <0x0 0xf0c30000 0x0 0x1000>;
                        clock-names = "apb_pclk";
                        status = "disabled";
                        clocks = <&versal_clk 0x52>;

                        in-ports {

                                port {

                                        etf_in_port: endpoint {
                                                phandle = <0xba>;
                                                remote-endpoint = <&funnel_out_port>;
                                        };
                                };
                        };

                        out-ports {

                                port {

                                        apu_etf_out_port: endpoint {
                                                phandle = <0xb1>;
                                                remote-endpoint = <&fpd_funnel_in_port1>;
                                        };
                                };
                        };
                };

                cpu0_debug: cpu0-debug@f0d00000 {
                        phandle = <0x16b>;
                        compatible = "arm,coresight-cpu-debug", "arm,primecell";
                        reg = <0x0 0xf0d00000 0x0 0x1000>;
                        clock-names = "apb_pclk";
                        cpu = <&psv_cortexa72_0>;
                        status = "disabled";
                        clocks = <&versal_clk 0x52>;
                };

                etm0: etm@f0d30000 {
                        phandle = <0x16c>;
                        compatible = "arm,coresight-etm4x", "arm,primecell";
                        reg = <0x0 0xf0d30000 0x0 0x1000>;
                        clock-names = "apb_pclk";
                        cpu = <&psv_cortexa72_0>;
                        status = "disabled";
                        clocks = <&versal_clk 0x52>;

                        out-ports {

                                port {

                                        etm0_out_port: endpoint {
                                                phandle = <0xb8>;
                                                remote-endpoint = <&funnel_in_port0>;
                                        };
                                };
                        };
                };

                cpu1_debug: cpu1-debug@f0d40000 {
                        phandle = <0x16d>;
                        compatible = "arm,coresight-cpu-debug", "arm,primecell";
                        reg = <0x0 0xf0d40000 0x0 0x1000>;
                        clock-names = "apb_pclk";
                        cpu = <&psv_cortexa72_1>;
                        status = "disabled";
                        clocks = <&versal_clk 0x52>;
                };

                etm1: etm@f0d70000 {
                        phandle = <0x16e>;
                        compatible = "arm,coresight-etm4x", "arm,primecell";
                        reg = <0x0 0xf0d70000 0x0 0x1000>;
                        clock-names = "apb_pclk";
                        cpu = <&psv_cortexa72_1>;
                        status = "disabled";
                        clocks = <&versal_clk 0x52>;

                        out-ports {

                                port {

                                        etm1_out_port: endpoint {
                                                phandle = <0xb9>;
                                                remote-endpoint = <&funnel_in_port1>;
                                        };
                                };
                        };
                };
        };

        pl_alt_ref: pl-alt-ref {
                phandle = <0xc2>;
                bootph-all;
                compatible = "fixed-clock";
                #clock-cells = <0x0>;
                clock-frequency = <0x1fca055>;
                clock-output-names = "pl_alt_ref_clk";
        };

        ref: ref {
                phandle = <0xc1>;
                bootph-all;
                compatible = "fixed-clock";
                #clock-cells = <0x0>;
                clock-frequency = <0x1fca055>;
                clock-output-names = "ref_clk";
        };

        rtc_clk: rtc-clk {
                phandle = <0xad>;
                bootph-all;
                compatible = "fixed-clock";
                #clock-cells = <0x0>;
                clock-frequency = <0x8000>;
                clock-output-names = "rtc_clk";
        };

        can0_clk: can0-clk {
                phandle = <0xab>;
                #clock-cells = <0x0>;
                compatible = "fixed-factor-clock";
                clocks = <&versal_clk 0x60>;
                clock-div = <0x2>;
                clock-mult = <0x1>;
                clock-output-names = "can0_clk";
        };

        can1_clk: can1-clk {
                phandle = <0xac>;
                #clock-cells = <0x0>;
                compatible = "fixed-factor-clock";
                clocks = <&versal_clk 0x61>;
                clock-div = <0x2>;
                clock-mult = <0x1>;
                clock-output-names = "can1_clk";
        };

        firmware {

                versal_firmware: versal-firmware {
                        phandle = <0x8d>;
                        compatible = "xlnx,versal-firmware";
                        interrupt-parent = <&gic>;
                        bootph-all;
                        method = "smc";
                        #power-domain-cells = <0x1>;

                        versal_clk: clock-controller {
                                phandle = <0x8f>;
                                bootph-all;
                                #clock-cells = <0x1>;
                                compatible = "xlnx,versal-clk";
                                clocks = <&ref>,
                                 <&pl_alt_ref>;
                                clock-names = "ref", "pl_alt_ref";
                        };

                        zynqmp_power: power-management {
                                phandle = <0x16f>;
                                compatible = "xlnx,zynqmp-power";
                        };

                        versal_reset: reset-controller {
                                phandle = <0xae>;
                                compatible = "xlnx,versal-reset";
                                #reset-cells = <0x1>;
                        };

                        pinctrl0: pinctrl {
                                phandle = <0x170>;
                                compatible = "xlnx,versal-pinctrl";
                        };

                        versal_sec_cfg: versal-sec-cfg {
                                phandle = <0x171>;
                                compatible = "xlnx,versal-sec-cfg";

                                nvmem-layout {
                                        compatible = "fixed-layout";
                                        #address-cells = <0x1>;
                                        #size-cells = <0x1>;

                                        bbram_zeroize: bbram-zeroize@4 {
                                                phandle = <0x172>;
                                                reg = <0x4 0x4>;
                                        };

                                        bbram_key: bbram-key@10 {
                                                phandle = <0x173>;
                                                reg = <0x10 0x20>;
                                        };

                                        bbram_usr: bbram-usr@30 {
                                                phandle = <0x174>;
                                                reg = <0x30 0x4>;
                                        };

                                        bbram_lock: bbram-lock@48 {
                                                phandle = <0x175>;
                                                reg = <0x48 0x4>;
                                        };

                                        user_key0: user-key@110 {
                                                phandle = <0x176>;
                                                reg = <0x110 0x20>;
                                        };

                                        user_key1: user-key@130 {
                                                phandle = <0x177>;
                                                reg = <0x130 0x20>;
                                        };

                                        user_key2: user-key@150 {
                                                phandle = <0x178>;
                                                reg = <0x150 0x20>;
                                        };

                                        user_key3: user-key@170 {
                                                phandle = <0x179>;
                                                reg = <0x170 0x20>;
                                        };

                                        user_key4: user-key@190 {
                                                phandle = <0x17a>;
                                                reg = <0x190 0x20>;
                                        };

                                        user_key5: user-key@1b0 {
                                                phandle = <0x17b>;
                                                reg = <0x1b0 0x20>;
                                        };

                                        user_key6: user-key@1d0 {
                                                phandle = <0x17c>;
                                                reg = <0x1d0 0x20>;
                                        };

                                        user_key7: user-key@1f0 {
                                                phandle = <0x17d>;
                                                reg = <0x1f0 0x20>;
                                        };
                                };
                        };
                };
        };

        axi_noc_mc_ddr4_0_ddr_memory: memory@00000000 {
                phandle = <0x4>;
                compatible = "xlnx,axi-noc-1.1";
                xlnx,ip-name = "axi_noc";
                device_type = "memory";
                reg = <0x0 0x0 0x0 0x80000000>;
                memory_type = "memory";
        };

        chosen {
                stdout-path = "serial1:115200n8";
                bootargs = "console=ttyAMA1 earlycon=pl011,mmio32,0xFF010000,115200n8";
        };

        aliases {
                serial0 = "/axi/serial@ff000000";
                spi0 = "/axi/spi@f1010000";
                serial1 = "/axi/serial@ff010000";
                serial2 = "/axi/coresight@f0800000";
                i2c0 = "/axi/i2c@ff020000";
                i2c1 = "/axi/i2c@ff030000";
        };

        onewire {
                compatible = "w1-gpio";
                gpios = <&gpio0 0x4 0x0>;
        };

        __symbols__ {
                cpus_a72 = "/cpus-a72@0";
                psv_cortexa72_0 = "/cpus-a72@0/cpu@0";
                psv_cortexa72_1 = "/cpus-a72@0/cpu@1";
                CPU_SLEEP_0 = "/cpus-a72@0/idle-states/cpu-sleep-0";
                l2 = "/l2-cache";
                cpu_opp_table = "/opp-table-cpu";
                dcc = "/dcc";
                fpga = "/fpga-region";
                psci = "/psci";
                timer = "/timer";
                versal_fpga = "/versal-fpga";
                sensor0 = "/versal-thermal-sensor";
                versal_thermal = "/thermal-zones/versal-thermal";
                temp_alert = "/thermal-zones/versal-thermal/trips/temp-alert";
                ot_crit = "/thermal-zones/versal-thermal/trips/ot-crit";
                versal_thermal_aie = "/thermal-zones/versal-aie-thermal";
                temp_alert_aie = "/thermal-zones/versal-aie-thermal/trips/temp-alert-aie";
                ot_crit_aie = "/thermal-zones/versal-aie-thermal/trips/ot-crit-aie";
                amba_apu = "/apu-bus";
                gic_its = "/axi/interrupt-controller@f9000000/msi-controller@f9020000";
                amba = "/axi";
                imux = "/axi/interrupt-multiplex";
                can0 = "/axi/can@ff060000";
                can1 = "/axi/can@ff070000";
                cci = "/axi/cci@fd000000";
                cci_pmu = "/axi/cci@fd000000/pmu@10000";
                lpd_dma_chan0 = "/axi/dma-controller@ffa80000";
                lpd_dma_chan1 = "/axi/dma-controller@ffa90000";
                lpd_dma_chan2 = "/axi/dma-controller@ffaa0000";
                lpd_dma_chan3 = "/axi/dma-controller@ffab0000";
                lpd_dma_chan4 = "/axi/dma-controller@ffac0000";
                lpd_dma_chan5 = "/axi/dma-controller@ffad0000";
                lpd_dma_chan6 = "/axi/dma-controller@ffae0000";
                lpd_dma_chan7 = "/axi/dma-controller@ffaf0000";
                gem0 = "/axi/ethernet@ff0c0000";
                gem1 = "/axi/ethernet@ff0d0000";
                gpio0 = "/axi/gpio@ff0b0000";
                gpio1 = "/axi/gpio@f1020000";
                i2c0 = "/axi/i2c@ff020000";
                i2c1 = "/axi/i2c@ff030000";
                i2c2 = "/axi/i2c@f1000000";
                mc0 = "/axi/memory-controller@f6150000";
                mc1 = "/axi/memory-controller@f62c0000";
                mc2 = "/axi/memory-controller@f6430000";
                mc3 = "/axi/memory-controller@f65a0000";
                ocm = "/axi/memory-controller@ff960000";
                rtc = "/axi/rtc@f12a0000";
                sdhci0 = "/axi/mmc@f1040000";
                sdhci1 = "/axi/mmc@f1050000";
                serial0 = "/axi/serial@ff000000";
                serial1 = "/axi/serial@ff010000";
                smmu = "/axi/iommu@fd800000";
                ospi = "/axi/spi@f1010000";
                qspi = "/axi/spi@f1030000";
                spi0 = "/axi/spi@ff040000";
                spi1 = "/axi/spi@ff050000";
                sysmon0 = "/axi/sysmon@f1270000";
                sysmon1 = "/axi/sysmon@109270000";
                sysmon2 = "/axi/sysmon@111270000";
                sysmon3 = "/axi/sysmon@119270000";
                ttc0 = "/axi/timer@ff0e0000";
                ttc1 = "/axi/timer@ff0f0000";
                ttc2 = "/axi/timer@ff100000";
                ttc3 = "/axi/timer@ff110000";
                usb0 = "/axi/usb@ff9d0000";
                dwc3_0 = "/axi/usb@ff9d0000/usb@fe200000";
                cpm_pciea = "/axi/pci@fca10000";
                pcie_intc_0 = "/axi/pci@fca10000/interrupt-controller";
                cpm5_pcie = "/axi/pcie@fcdd0000";
                pcie_intc_2 = "/axi/pcie@fcdd0000/interrupt-controller";
                watchdog = "/axi/watchdog@fd4d0000";
                watchdog1 = "/axi/watchdog@ff120000";
                xilsem_edac = "/axi/edac@f2014050";
                dma0 = "/axi/pmcdma@f11c0000";
                dma1 = "/axi/pmcdma@f11d0000";
                ipi0 = "/axi/mailbox@ff330000";
                ipi_0_to_ipi_0 = "/axi/mailbox@ff330000/child@ff330000";
                ipi_0_to_ipi_1 = "/axi/mailbox@ff330000/child@ff340000";
                ipi_0_to_ipi_2 = "/axi/mailbox@ff330000/child@ff350000";
                ipi_0_to_ipi_3 = "/axi/mailbox@ff330000/child@ff360000";
                ipi_0_to_ipi_4 = "/axi/mailbox@ff330000/child@ff370000";
                ipi_0_to_ipi_5 = "/axi/mailbox@ff330000/child@ff380000";
                ipi_0_to_ipi_6 = "/axi/mailbox@ff330000/child@ff3a0000";
                ipi_0_to_ipi_pmc = "/axi/mailbox@ff330000/child@ff320000";
                ipi_0_to_ipi_pmc_nobuf = "/axi/mailbox@ff330000/child@ff390000";
                ipi_0_to_ipi_psm = "/axi/mailbox@ff330000/child@ff310000";
                ipi1 = "/axi/mailbox@ff340000";
                ipi_1_to_ipi_0 = "/axi/mailbox@ff340000/child@ff330000";
                ipi_1_to_ipi_1 = "/axi/mailbox@ff340000/child@ff340000";
                ipi_1_to_ipi_2 = "/axi/mailbox@ff340000/child@ff350000";
                ipi_1_to_ipi_3 = "/axi/mailbox@ff340000/child@ff360000";
                ipi_1_to_ipi_4 = "/axi/mailbox@ff340000/child@ff370000";
                ipi_1_to_ipi_5 = "/axi/mailbox@ff340000/child@ff380000";
                ipi_1_to_ipi_6 = "/axi/mailbox@ff340000/child@ff3a0000";
                ipi_1_to_ipi_pmc = "/axi/mailbox@ff340000/child@ff320000";
                ipi_1_to_ipi_pmc_nobuf = "/axi/mailbox@ff340000/child@ff390000";
                ipi_1_to_ipi_psm = "/axi/mailbox@ff340000/child@ff310000";
                ipi2 = "/axi/mailbox@ff350000";
                ipi_2_to_ipi_0 = "/axi/mailbox@ff350000/child@ff330000";
                ipi_2_to_ipi_1 = "/axi/mailbox@ff350000/child@ff340000";
                ipi_2_to_ipi_2 = "/axi/mailbox@ff350000/child@ff350000";
                ipi_2_to_ipi_3 = "/axi/mailbox@ff350000/child@ff360000";
                ipi_2_to_ipi_4 = "/axi/mailbox@ff350000/child@ff370000";
                ipi_2_to_ipi_5 = "/axi/mailbox@ff350000/child@ff380000";
                ipi_2_to_ipi_6 = "/axi/mailbox@ff350000/child@ff3a0000";
                ipi_2_to_ipi_pmc = "/axi/mailbox@ff350000/child@ff320000";
                ipi_2_to_ipi_pmc_nobuf = "/axi/mailbox@ff350000/child@ff390000";
                ipi_2_to_ipi_psm = "/axi/mailbox@ff350000/child@ff310000";
                coresight = "/axi/coresight@f0800000";
                cips_pspmc_0_psv_coresight_fpd_cti1b = "/axi/cips_pspmc_0_psv_coresight_fpd_cti1b@f0bb0000";
                cips_pspmc_0_psv_coresight_fpd_cti1c = "/axi/cips_pspmc_0_psv_coresight_fpd_cti1c@f0bc0000";
                cips_pspmc_0_psv_coresight_fpd_cti1d = "/axi/cips_pspmc_0_psv_coresight_fpd_cti1d@f0bd0000";
                cips_pspmc_0_psv_coresight_lpd_cti = "/axi/cips_pspmc_0_psv_coresight_lpd_cti@f09d0000";
                cips_pspmc_0_psv_coresight_pmc_cti = "/axi/cips_pspmc_0_psv_coresight_pmc_cti@f08d0000";
                cips_pspmc_0_psv_coresight_r50_cti = "/axi/cips_pspmc_0_psv_coresight_r50_cti@f0a10000";
                cips_pspmc_0_psv_coresight_r51_cti = "/axi/cips_pspmc_0_psv_coresight_r51_cti@f0a50000";
                cips_pspmc_0_psv_cpm = "/axi/cips_pspmc_0_psv_cpm@0";
                cips_pspmc_0_psv_pmc_analog_0 = "/axi/cips_pspmc_0_psv_pmc_analog_0@f1160000";
                cips_pspmc_0_psv_pmc_iou_slcr_0 = "/axi/cips_pspmc_0_psv_pmc_iou_slcr_0@f1060000";
                cips_pspmc_0_psv_pmc_tap = "/axi/cips_pspmc_0_psv_pmc_tap@f11a0000";
                amba_xppu = "/indirect-bus@1";
                lpd_xppu = "/indirect-bus@1/xppu@ff990000";
                pmc_xppu = "/indirect-bus@1/xppu@f1310000";
                pmc_xppu_npi = "/indirect-bus@1/xppu@f1300000";
                amba_xmpu = "/indirect-bus@2";
                fpd_xmpu = "/indirect-bus@2/xmpu@fd390000";
                pmc_xmpu = "/indirect-bus@2/xmpu@f12f0000";
                ocm_xmpu = "/indirect-bus@2/xmpu@ff980000";
                ddrmc_xmpu_0 = "/indirect-bus@2/xmpu@f6080000";
                ddrmc_xmpu_1 = "/indirect-bus@2/xmpu@f6220000";
                ddrmc_xmpu_2 = "/indirect-bus@2/xmpu@f6390000";
                ddrmc_xmpu_3 = "/indirect-bus@2/xmpu@f6500000";
                fpd_funnel = "/indirect-bus@2/fpd-funnel@f0b20000";
                fpd_funnel_in_port1 = "/indirect-bus@2/fpd-funnel@f0b20000/in-ports/port@1/endpoint";
                fpd_funnel_out_port = "/indirect-bus@2/fpd-funnel@f0b20000/out-ports/port/endpoint";
                fpd_etf = "/indirect-bus@2/fpd-etf@f0b30000";
                fpd_etf_in_port = "/indirect-bus@2/fpd-etf@f0b30000/in-ports/port/endpoint";
                fpd_etf_out_port = "/indirect-bus@2/fpd-etf@f0b30000/out-ports/port/endpoint";
                replicator = "/indirect-bus@2/replicator@f0b40000";
                replicator_in_port = "/indirect-bus@2/replicator@f0b40000/in-ports/port/endpoint";
                replicator_out_port0 = "/indirect-bus@2/replicator@f0b40000/out-ports/port@0/endpoint";
                etr = "/indirect-bus@2/etr@f0b50000";
                etr_in_port = "/indirect-bus@2/etr@f0b50000/in-ports/port/endpoint";
                apu_funnel = "/indirect-bus@2/funnel@f0c20000";
                funnel_in_port0 = "/indirect-bus@2/funnel@f0c20000/in-ports/port@0/endpoint";
                funnel_in_port1 = "/indirect-bus@2/funnel@f0c20000/in-ports/port@1/endpoint";
                funnel_out_port = "/indirect-bus@2/funnel@f0c20000/out-ports/port/endpoint";
                apu_etf = "/indirect-bus@2/etf@f0c30000";
                etf_in_port = "/indirect-bus@2/etf@f0c30000/in-ports/port/endpoint";
                apu_etf_out_port = "/indirect-bus@2/etf@f0c30000/out-ports/port/endpoint";
                cpu0_debug = "/indirect-bus@2/cpu0-debug@f0d00000";
                etm0 = "/indirect-bus@2/etm@f0d30000";
                etm0_out_port = "/indirect-bus@2/etm@f0d30000/out-ports/port/endpoint";
                cpu1_debug = "/indirect-bus@2/cpu1-debug@f0d40000";
                etm1 = "/indirect-bus@2/etm@f0d70000";
                etm1_out_port = "/indirect-bus@2/etm@f0d70000/out-ports/port/endpoint";
                pl_alt_ref = "/pl-alt-ref";
                ref = "/ref";
                rtc_clk = "/rtc-clk";
                can0_clk = "/can0-clk";
                can1_clk = "/can1-clk";
                versal_firmware = "/firmware/versal-firmware";
                versal_clk = "/firmware/versal-firmware/clock-controller";
                zynqmp_power = "/firmware/versal-firmware/power-management";
                versal_reset = "/firmware/versal-firmware/reset-controller";
                pinctrl0 = "/firmware/versal-firmware/pinctrl";
                versal_sec_cfg = "/firmware/versal-firmware/versal-sec-cfg";
                bbram_zeroize = "/firmware/versal-firmware/versal-sec-cfg/nvmem-layout/bbram-zeroize@4";
                bbram_key = "/firmware/versal-firmware/versal-sec-cfg/nvmem-layout/bbram-key@10";
                bbram_usr = "/firmware/versal-firmware/versal-sec-cfg/nvmem-layout/bbram-usr@30";
                bbram_lock = "/firmware/versal-firmware/versal-sec-cfg/nvmem-layout/bbram-lock@48";
                user_key0 = "/firmware/versal-firmware/versal-sec-cfg/nvmem-layout/user-key@110";
                user_key1 = "/firmware/versal-firmware/versal-sec-cfg/nvmem-layout/user-key@130";
                user_key2 = "/firmware/versal-firmware/versal-sec-cfg/nvmem-layout/user-key@150";
                user_key3 = "/firmware/versal-firmware/versal-sec-cfg/nvmem-layout/user-key@170";
                user_key4 = "/firmware/versal-firmware/versal-sec-cfg/nvmem-layout/user-key@190";
                user_key5 = "/firmware/versal-firmware/versal-sec-cfg/nvmem-layout/user-key@1b0";
                user_key6 = "/firmware/versal-firmware/versal-sec-cfg/nvmem-layout/user-key@1d0";
                user_key7 = "/firmware/versal-firmware/versal-sec-cfg/nvmem-layout/user-key@1f0";
                axi_noc_mc_ddr4_0_ddr_memory = "/memory@00000000";
                axi_noc_cips_hbm_memory = "/memory@4000000000";
                axi_noc_mc_ddr4_1_ddr_memory = "/memory@60000000000";
                rpu0_runtime_region = "/reserved-memory/rpu0_runtime_region@0";
                rpu0_shared_region = "/reserved-memory/rpu0_shared_region@10000000";
                rpu1_runtime_region = "/reserved-memory/rpu1_runtime_region@10800000";
                gic = "/axi/interrupt-controller@f9000000";
        };

        domains {

                APU_Linux {
                        compatible = "openamp,domain-v1";
                        reserved-memory = <0x17f 0x180 0x181>;
                        cpus = <&cpus_a72 0xf 0x80000003>;
                        os,type = "linux";

                        chosen {
                                stdout-path = "serial1:115200n8";
                                bootargs = "console=ttyAMA1 earlycon=pl011,mmio32,0xFF010000,115200n8";
                        };
                };
        };

        reserved-memory {
                #size-cells = <0x2>;
                #address-cells = <0x2>;
                ranges;

                rpu0_runtime_region: rpu0_runtime_region@0 {
                        phandle = <0x17f>;
                        label = "rpu0_runtime_region";
                        no-map;
                        reg = <0x0 0x0 0x0 0x10000000>;
                };

                rpu0_shared_region: rpu0_shared_region@10000000 {
                        phandle = <0x180>;
                        label = "rpu0_shared_region";
                        no-map;
                        reg = <0x0 0x10000000 0x0 0x800000>;
                };

                rpu1_runtime_region: rpu1_runtime_region@10800000 {
                        phandle = <0x181>;
                        label = "rpu1_runtime_region";
                        no-map;
                        reg = <0x0 0x10800000 0x0 0x4000000>;
                };
        };
};
